VERSION "..\..\trunk\components\winTestMT\code\canApi\dbcFiles\canBus_09.dbc, created by Octave and generateRandomDbc.m on 21-Feb-2017"

NS_ :

BS_:

BU_: ECU

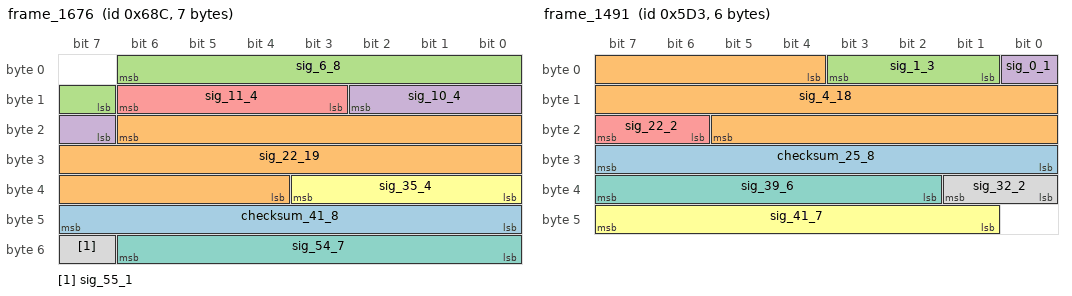
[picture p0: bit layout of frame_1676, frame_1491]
BO_ 1676 frame_1676: 7 ECU
  SG_ checksum_41_8 : 40|8@1+ (1.0,0.0) [0.0|255.0] "" Vector__XXX
  SG_ sig_22_19 : 22|19@0+ (0.1,31622.776601683792) [31622.776601683792|84051.37660168379] "km/h" Vector__XXX
  SG_ sig_6_8 : 6|8@0+ (10.0,-316.22776601683796) [-316.22776601683796|2223.772233983162] "W" Vector__XXX
  SG_ sig_10_4 : 10|4@0+ (1.0000000000000006E-5,-3.1622776601683795E-5) [-3.1622776601683795E-5|1.0837722339831631E-4] "s" Vector__XXX
  SG_ sig_11_4 : 11|4@1+ (1000.0,-3162.2776601683795) [-3162.2776601683795|10837.72233983162] "kWh" Vector__XXX
  SG_ sig_35_4 : 35|4@0+ (0.0010000000000000002,0.0) [0.0|0.014000000000000004] "s" Vector__XXX
  SG_ sig_54_7 : 54|7@0+ (1000.0,0.0) [0.0|126000.0] "s" Vector__XXX
  SG_ sig_55_1 : 55|1@0+ (1.0,0.0) [0.0|1.0] "" Vector__XXX

BO_ 1012 frame_1012: 4 Vector__XXX
  SG_ checksum_1_8 : 0|8@1+ (1.0,0.0) [0.0|255.0] "" ECU
  SG_ sig_8_14 : 8|14@0- (1.0,0.0) [-8192.0|8190.0] "" ECU
  SG_ sig_9_7 : 9|7@1+ (0.0010000000000000002,0.03162277660168379) [0.03162277660168379|0.15762277660168383] "km/h" ECU
  SG_ sig_24_3 : 24|3@1- (1.0,0.0) [-4.0|2.0] "" ECU

BO_ 1491 frame_1491: 6 ECU
  SG_ checksum_25_8 : 24|8@1+ (1.0,0.0) [0.0|255.0] "" Vector__XXX
  SG_ sig_4_18 : 4|18@1+ (1.0,0.0) [0.0|262142.0] "" Vector__XXX
  SG_ sig_1_3 : 1|3@1- (1.0,0.0) [-4.0|2.0] "" Vector__XXX
  SG_ sig_0_1 : 0|1@0+ (1.0,0.0) [0.0|1.0] "" Vector__XXX
  SG_ sig_22_2 : 22|2@1+ (1.0,0.0) [0.0|3.0] "" Vector__XXX
  SG_ sig_41_7 : 41|7@1+ (1.0,0.0) [0.0|126.0] "" Vector__XXX
  SG_ sig_39_6 : 39|6@0+ (1.0000000000000005E-4,0.0) [0.0|0.006200000000000002] "m/s^2" Vector__XXX
  SG_ sig_32_2 : 32|2@1- (1.0,0.0) [-2.0|1.0] "" Vector__XXX

BO_ 1536 frame_1536: 4 ECU
  SG_ checksum_9_8 : 15|8@0+ (1.0,0.0) [0.0|255.0] "" Vector__XXX
  SG_ sig_6_7 : 6|7@0- (1.0000000000000006E-6,0.0) [-6.400000000000004E-5|6.200000000000004E-5] "kWh" Vector__XXX
  SG_ sig_7_1 : 7|1@0+ (1.0,0.0) [0.0|1.0] "" Vector__XXX
  SG_ sig_17_10 : 17|10@0+ (1.0,0.0) [0.0|1022.0] "" Vector__XXX
  SG_ sig_19_2 : 19|2@0- (1.0,0.0) [-2.0|1.0] "" Vector__XXX

BO_ 499 frame_499: 4 Vector__XXX
  SG_ checksum_17_8 : 16|8@1+ (1.0,0.0) [0.0|255.0] "" ECU
  SG_ sig_1_15 : 1|15@1+ (1.0,0.0) [0.0|32766.0] "" ECU
  SG_ sig_0_1 : 0|1@1+ (1.0,0.0) [0.0|1.0] "" ECU
  SG_ sig_28_5 : 28|5@0+ (1.0,0.0) [0.0|30.0] "" ECU
  SG_ sig_31_3 : 31|3@0+ (1.0,0.0) [0.0|6.0] "" ECU

BO_ 621 frame_621: 4 ECU
  SG_ checksum_25_8 : 31|8@0+ (1.0,0.0) [0.0|255.0] "" Vector__XXX
  SG_ sig_3_14 : 3|14@0+ (1.0000000000000006E-6,0.0) [0.0|0.01638200000000001] "km/h" Vector__XXX
  SG_ sig_7_4 : 7|4@0+ (1.0,0.0) [0.0|14.0] "" Vector__XXX
  SG_ sig_20_5 : 20|5@0- (1.0,0.0) [-16.0|14.0] "" Vector__XXX
  SG_ sig_21_1 : 21|1@0+ (1.0,0.0) [0.0|1.0] "" Vector__XXX

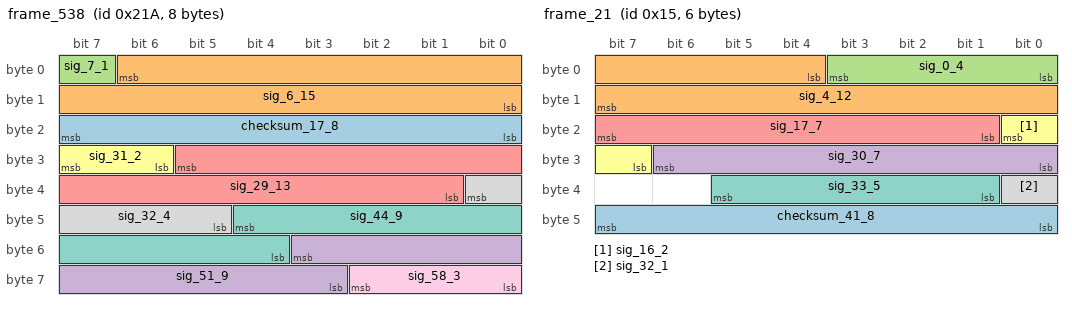
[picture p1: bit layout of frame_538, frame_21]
BO_ 538 frame_538: 8 ECU
  SG_ checksum_17_8 : 16|8@1+ (1.0,0.0) [0.0|255.0] "" Vector__XXX
  SG_ sig_6_15 : 6|15@0- (1.0,31622.776601683792) [15238.776601683792|48004.77660168379] "km/h" Vector__XXX
  SG_ sig_7_1 : 7|1@1+ (1.0,0.0) [0.0|1.0] "" Vector__XXX
  SG_ sig_51_9 : 51|9@0+ (1.0000000000000006E-5,0.0) [0.0|0.005100000000000003] "km/h" Vector__XXX
  SG_ sig_29_13 : 29|13@0+ (1.0,0.0) [0.0|8190.0] "" Vector__XXX
  SG_ sig_31_2 : 31|2@0- (1.0,0.0) [-2.0|1.0] "" Vector__XXX
  SG_ sig_44_9 : 44|9@0+ (1.0000000000000007E-7,-3.1622776601683795E-5) [-3.1622776601683795E-5|1.9377223398316245E-5] "s" Vector__XXX
  SG_ sig_32_4 : 32|4@0- (0.0010000000000000002,0.0) [-0.008000000000000002|0.006000000000000002] "W" Vector__XXX
  SG_ sig_58_3 : 58|3@0- (1.0,0.0) [-4.0|2.0] "" Vector__XXX

BO_ 1384 frame_1384: 7 ECU
  SG_ checksum_9_8 : 8|8@1+ (1.0,0.0) [0.0|255.0] "" Vector__XXX
  SG_ sig_0_7 : 0|7@1- (0.0010000000000000002,0.03162277660168379) [-0.032377223398316224|0.0936227766016838] "A" Vector__XXX
  SG_ sig_27_19 : 27|19@0+ (0.1,0.0) [0.0|52428.600000000006] "A" Vector__XXX
  SG_ sig_16_7 : 16|7@1+ (1.0,0.0) [0.0|126.0] "" Vector__XXX
  SG_ sig_28_4 : 28|4@1+ (1.0000000000000006E-6,3.162277660168379E-6) [3.162277660168379E-6|1.7162277660168386E-5] "km/h" Vector__XXX
  SG_ sig_48_8 : 48|8@1- (0.010000000000000002,0.0) [-1.2800000000000002|1.2600000000000002] "m/s^2" Vector__XXX

BO_ 993 frame_993: 7 Vector__XXX
  SG_ checksum_25_8 : 24|8@1+ (1.0,0.0) [0.0|255.0] "" ECU
  SG_ sig_0_18 : 0|18@1+ (1.0,0.0) [0.0|262142.0] "" ECU
  SG_ sig_18_6 : 18|6@1+ (1000.0,31622.776601683792) [31622.776601683792|93622.77660168378] "kWh" ECU
  SG_ sig_39_16 : 39|16@0+ (1.0,0.0) [0.0|65534.0] "" ECU
  SG_ sig_48_8 : 48|8@1+ (1.0000000000000005E-4,0.0031622776601683794) [0.0031622776601683794|0.028562277660168393] "km/h" ECU

BO_ 21 frame_21: 6 ECU
  SG_ checksum_41_8 : 47|8@0+ (1.0,0.0) [0.0|255.0] "" Vector__XXX
  SG_ sig_4_12 : 4|12@1- (10.0,31622.776601683792) [11142.776601683792|52082.77660168379] "W" Vector__XXX
  SG_ sig_0_4 : 0|4@1- (100.0,0.0) [-800.0|600.0] "kWh" Vector__XXX
  SG_ sig_30_7 : 30|7@0- (1.0,0.0) [-64.0|62.0] "" Vector__XXX
  SG_ sig_17_7 : 17|7@1- (1.0,0.0) [-64.0|62.0] "" Vector__XXX
  SG_ sig_16_2 : 16|2@0+ (1.0,0.0) [0.0|3.0] "" Vector__XXX
  SG_ sig_33_5 : 33|5@1- (1.0000000000000005E-4,-0.0031622776601683794) [-0.0047622776601683806|-0.0017622776601683788] "kWh" Vector__XXX
  SG_ sig_32_1 : 32|1@1+ (1.0,0.0) [0.0|1.0] "" Vector__XXX

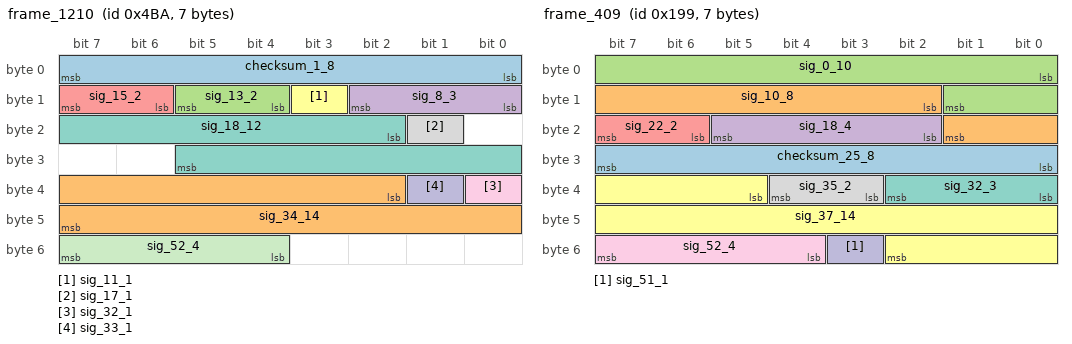
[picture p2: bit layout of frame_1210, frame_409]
BO_ 1210 frame_1210: 7 Vector__XXX
  SG_ checksum_1_8 : 7|8@0+ (1.0,0.0) [0.0|255.0] "" ECU
  SG_ sig_34_14 : 34|14@1- (10.0,-31622.776601683792) [-113542.77660168378|50277.22339831621] "km/h" ECU
  SG_ sig_13_2 : 13|2@0+ (1.0,0.0) [0.0|3.0] "" ECU
  SG_ sig_8_3 : 8|3@1- (1.0,0.0) [-4.0|2.0] "" ECU
  SG_ sig_15_2 : 15|2@0- (1.0,0.0) [-2.0|1.0] "" ECU
  SG_ sig_11_1 : 11|1@0+ (1.0,0.0) [0.0|1.0] "" ECU
  SG_ sig_18_12 : 18|12@1+ (1.0000000000000008E-8,0.0) [0.0|4.094000000000003E-5] "km/h" ECU
  SG_ sig_17_1 : 17|1@1+ (1.0,0.0) [0.0|1.0] "" ECU
  SG_ sig_32_1 : 32|1@1+ (1.0,0.0) [0.0|1.0] "" ECU
  SG_ sig_33_1 : 33|1@1+ (1.0,0.0) [0.0|1.0] "" ECU
  SG_ sig_52_4 : 52|4@1+ (1000.0,-3162.2776601683795) [-3162.2776601683795|10837.72233983162] "m/s^2" ECU

BO_ 566 frame_566: 6 Vector__XXX
  SG_ checksum_17_8 : 23|8@0+ (1.0,0.0) [0.0|255.0] "" ECU
  SG_ sig_6_14 : 6|14@0+ (1.0,0.0) [0.0|16382.0] "" ECU
  SG_ sig_7_1 : 7|1@0+ (1.0,0.0) [0.0|1.0] "" ECU
  SG_ sig_8_1 : 8|1@0+ (1.0,0.0) [0.0|1.0] "" ECU
  SG_ sig_31_16 : 31|16@0- (1.0,31622.776601683792) [-1145.2233983162077|64388.77660168379] "m/s^2" ECU
  SG_ sig_47_8 : 47|8@0+ (1.0,0.0) [0.0|254.0] "" ECU

BO_ 409 frame_409: 7 ECU
  SG_ checksum_25_8 : 24|8@1+ (1.0,0.0) [0.0|255.0] "" Vector__XXX
  SG_ sig_10_8 : 10|8@1- (100.0,0.0) [-12800.0|12600.0] "m/s^2" Vector__XXX
  SG_ sig_0_10 : 0|10@1- (1.0,0.0) [-512.0|510.0] "" Vector__XXX
  SG_ sig_18_4 : 18|4@1+ (10.0,0.0) [0.0|140.0] "s" Vector__XXX
  SG_ sig_22_2 : 22|2@1- (1.0,0.0) [-2.0|1.0] "" Vector__XXX
  SG_ sig_37_14 : 37|14@1- (1.0,0.0) [-8192.0|8190.0] "" Vector__XXX
  SG_ sig_32_3 : 32|3@1- (1.0,0.0) [-4.0|2.0] "" Vector__XXX
  SG_ sig_35_2 : 35|2@1- (1.0,0.0) [-2.0|1.0] "" Vector__XXX
  SG_ sig_52_4 : 52|4@1- (0.010000000000000002,0.0) [-0.08000000000000002|0.06000000000000001] "W" Vector__XXX
  SG_ sig_51_1 : 51|1@1+ (1.0,0.0) [0.0|1.0] "" Vector__XXX

BO_ 810 frame_810: 3 Vector__XXX
  SG_ checksum_9_8 : 8|8@1+ (1.0,0.0) [0.0|255.0] "" ECU
  SG_ sig_2_6 : 2|6@1+ (1.0,0.0) [0.0|62.0] "" ECU
  SG_ sig_0_2 : 0|2@1- (1.0,0.0) [-2.0|1.0] "" ECU
  SG_ sig_21_6 : 21|6@0- (1.0,0.0) [-32.0|30.0] "" ECU
  SG_ sig_23_2 : 23|2@0- (1.0,0.0) [-2.0|1.0] "" ECU

BO_ 1001 frame_1001: 5 Vector__XXX
  SG_ checksum_17_8 : 23|8@0+ (1.0,0.0) [0.0|255.0] "" ECU
  SG_ sig_3_12 : 3|12@1- (0.0010000000000000002,-3.1622776601683795) [-5.21027766016838|-1.1162776601683788] "W" ECU
  SG_ sig_2_4 : 2|4@0+ (1.0000000000000006E-6,3.162277660168379E-6) [3.162277660168379E-6|1.7162277660168386E-5] "km/h" ECU
  SG_ sig_31_13 : 31|13@0+ (1.0,0.0) [0.0|8190.0] "" ECU
  SG_ sig_32_1 : 32|1@0+ (1.0,0.0) [0.0|1.0] "" ECU

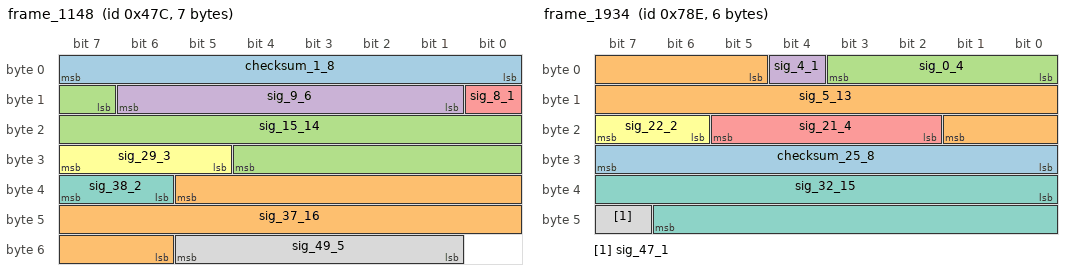
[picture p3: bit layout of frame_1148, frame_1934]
BO_ 1148 frame_1148: 7 ECU
  SG_ checksum_1_8 : 0|8@1+ (1.0,0.0) [0.0|255.0] "" Vector__XXX
  SG_ sig_37_16 : 37|16@0+ (0.010000000000000002,316.22776601683796) [316.22776601683796|971.567766016838] "s" Vector__XXX
  SG_ sig_15_14 : 15|14@1+ (0.1,316.22776601683796) [316.22776601683796|1954.427766016838] "A" Vector__XXX
  SG_ sig_9_6 : 9|6@1- (1000.0,31622.776601683792) [-377.22339831620775|61622.77660168379] "W" Vector__XXX
  SG_ sig_8_1 : 8|1@1+ (1.0,0.0) [0.0|1.0] "" Vector__XXX
  SG_ sig_29_3 : 29|3@1+ (1.0,0.0) [0.0|6.0] "" Vector__XXX
  SG_ sig_38_2 : 38|2@1+ (1.0,0.0) [0.0|3.0] "" Vector__XXX
  SG_ sig_49_5 : 49|5@1+ (100.0,-3162.2776601683795) [-3162.2776601683795|-162.2776601683795] "W" Vector__XXX

BO_ 1934 frame_1934: 6 ECU
  SG_ checksum_25_8 : 31|8@0+ (1.0,0.0) [0.0|255.0] "" Vector__XXX
  SG_ sig_5_13 : 5|13@1+ (1.0000000000000008E-8,-3.1622776601683795E-5) [-3.1622776601683795E-5|5.027722339831627E-5] "s" Vector__XXX
  SG_ sig_0_4 : 0|4@1- (1.0,0.0) [-8.0|6.0] "" Vector__XXX
  SG_ sig_4_1 : 4|1@0+ (1.0,0.0) [0.0|1.0] "" Vector__XXX
  SG_ sig_21_4 : 21|4@0+ (1.0000000000000006E-5,3.1622776601683795E-5) [3.1622776601683795E-5|1.7162277660168388E-4] "V" Vector__XXX
  SG_ sig_22_2 : 22|2@1+ (1.0,0.0) [0.0|3.0] "" Vector__XXX
  SG_ sig_32_15 : 32|15@1+ (1.0000000000000005E-4,3.1622776601683795) [3.1622776601683795|6.438877660168381] "kWh" Vector__XXX
  SG_ sig_47_1 : 47|1@0+ (1.0,0.0) [0.0|1.0] "" Vector__XXX

BO_ 1238 frame_1238: 6 Vector__XXX
  SG_ checksum_33_8 : 32|8@1+ (1.0,0.0) [0.0|255.0] "" ECU
  SG_ sig_1_16 : 1|16@1- (1.0000000000000005E-4,0.0) [-3.2768000000000015|3.2766000000000015] "m/s^2" ECU
  SG_ sig_0_1 : 0|1@1+ (1.0,0.0) [0.0|1.0] "" ECU
  SG_ sig_18_14 : 18|14@1- (10.0,-31622.776601683792) [-113542.77660168378|50277.22339831621] "kWh" ECU

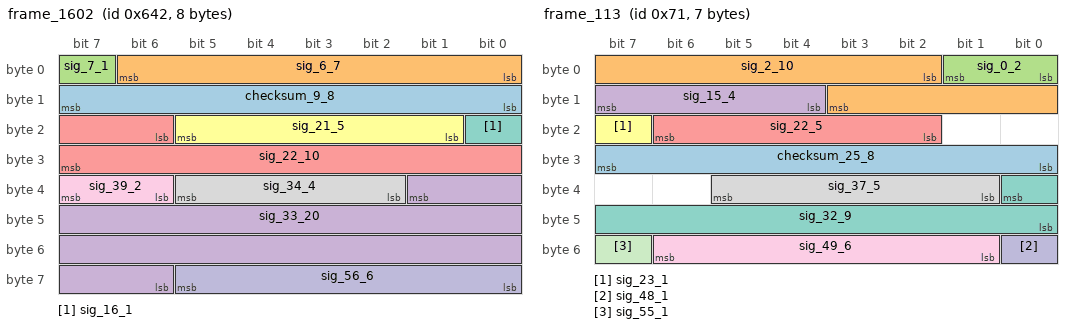
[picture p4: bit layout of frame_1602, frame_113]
BO_ 1602 frame_1602: 8 Vector__XXX
  SG_ checksum_9_8 : 15|8@0+ (1.0,0.0) [0.0|255.0] "" ECU
  SG_ sig_6_7 : 6|7@0+ (1.0,0.0) [0.0|126.0] "" ECU
  SG_ sig_7_1 : 7|1@0+ (1.0,0.0) [0.0|1.0] "" ECU
  SG_ sig_33_20 : 33|20@0- (1.0000000000000008E-8,0.0031622776601683794) [-0.002080602339831625|0.008405137660168384] "V" ECU
  SG_ sig_22_10 : 22|10@1- (0.010000000000000002,3.1622776601683795) [-1.9577223398316215|8.262277660168381] "kWh" ECU
  SG_ sig_21_5 : 21|5@0- (1.0000000000000005E-4,-0.0031622776601683794) [-0.0047622776601683806|-0.0017622776601683788] "V" ECU
  SG_ sig_16_1 : 16|1@1+ (1.0,0.0) [0.0|1.0] "" ECU
  SG_ sig_34_4 : 34|4@1+ (1.0,0.0) [0.0|14.0] "" ECU
  SG_ sig_39_2 : 39|2@0+ (1.0,0.0) [0.0|3.0] "" ECU
  SG_ sig_56_6 : 56|6@1+ (1.0000000000000007E-7,-3.162277660168379E-6) [-3.162277660168379E-6|3.037722339831626E-6] "km/h" ECU

BO_ 113 frame_113: 7 Vector__XXX
  SG_ checksum_25_8 : 24|8@1+ (1.0,0.0) [0.0|255.0] "" ECU
  SG_ sig_2_10 : 2|10@1+ (1.0,0.0) [0.0|1022.0] "" ECU
  SG_ sig_0_2 : 0|2@1- (1.0,0.0) [-2.0|1.0] "" ECU
  SG_ sig_15_4 : 15|4@0+ (1.0,0.0) [0.0|14.0] "" ECU
  SG_ sig_22_5 : 22|5@0- (1.0,0.0) [-16.0|14.0] "" ECU
  SG_ sig_23_1 : 23|1@0+ (1.0,0.0) [0.0|1.0] "" ECU
  SG_ sig_32_9 : 32|9@0- (1.0000000000000006E-6,-3.1622776601683794E-4) [-5.722277660168381E-4|-6.222776601683778E-5] "km/h" ECU
  SG_ sig_37_5 : 37|5@0- (1.0,0.0) [-16.0|14.0] "m/s^2" ECU
  SG_ sig_49_6 : 49|6@1- (1.0000000000000005E-4,0.0) [-0.0032000000000000015|0.0030000000000000014] "m/s^2" ECU
  SG_ sig_48_1 : 48|1@1+ (1.0,0.0) [0.0|1.0] "" ECU
  SG_ sig_55_1 : 55|1@0+ (1.0,0.0) [0.0|1.0] "" ECU

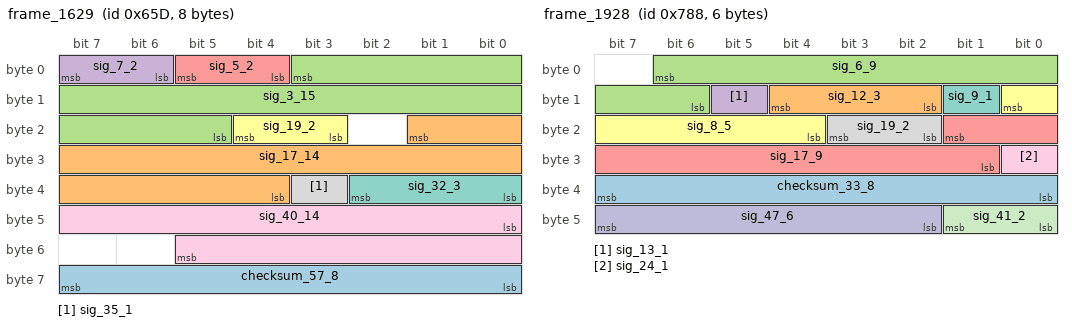
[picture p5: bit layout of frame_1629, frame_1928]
BO_ 1629 frame_1629: 8 Vector__XXX
  SG_ checksum_57_8 : 63|8@0+ (1.0,0.0) [0.0|255.0] "" ECU
  SG_ sig_17_14 : 17|14@0- (1.0,0.0) [-8192.0|8190.0] "s" ECU
  SG_ sig_3_15 : 3|15@0+ (1.0000000000000008E-8,-3.1622776601683794E-4) [-3.1622776601683794E-4|1.1432233983162349E-5] "km/h" ECU
  SG_ sig_7_2 : 7|2@0- (1.0,0.0) [-2.0|1.0] "" ECU
  SG_ sig_5_2 : 5|2@0+ (1.0,0.0) [0.0|3.0] "" ECU
  SG_ sig_19_2 : 19|2@1+ (1.0,0.0) [0.0|3.0] "" ECU
  SG_ sig_32_3 : 32|3@1+ (1.0,0.0) [0.0|6.0] "" ECU
  SG_ sig_35_1 : 35|1@1+ (1.0,0.0) [0.0|1.0] "" ECU
  SG_ sig_40_14 : 40|14@1- (1.0,0.0) [-8192.0|8190.0] "" ECU

BO_ 1928 frame_1928: 6 Vector__XXX
  SG_ checksum_33_8 : 39|8@0+ (1.0,0.0) [0.0|255.0] "" ECU
  SG_ sig_12_3 : 12|3@0+ (1.0,0.0) [0.0|6.0] "" ECU
  SG_ sig_6_9 : 6|9@0+ (1.0,0.0) [0.0|510.0] "V" ECU
  SG_ sig_13_1 : 13|1@0+ (1.0,0.0) [0.0|1.0] "" ECU
  SG_ sig_17_9 : 17|9@0- (1.0,0.0) [-256.0|254.0] "" ECU
  SG_ sig_8_5 : 8|5@0- (0.010000000000000002,0.31622776601683794) [0.1562277660168379|0.45622776601683795] "A" ECU
  SG_ sig_9_1 : 9|1@0+ (1.0,0.0) [0.0|1.0] "" ECU
  SG_ sig_19_2 : 19|2@0+ (1.0,0.0) [0.0|3.0] "" ECU
  SG_ sig_24_1 : 24|1@0+ (1.0,0.0) [0.0|1.0] "" ECU
  SG_ sig_47_6 : 47|6@0- (0.0010000000000000002,0.03162277660168379) [-3.7722339831621626E-4|0.0616227766016838] "s" ECU
  SG_ sig_41_2 : 41|2@0- (1.0,0.0) [-2.0|1.0] "" ECU

BO_ 1256 frame_1256: 6 Vector__XXX
  SG_ checksum_25_8 : 24|8@1+ (1.0,0.0) [0.0|255.0] "" ECU
  SG_ sig_5_20 : 5|20@0+ (1.0,0.0) [0.0|1048574.0] "" ECU
  SG_ sig_6_2 : 6|2@1+ (1.0,0.0) [0.0|3.0] "" ECU
  SG_ sig_16_2 : 16|2@1+ (1.0,0.0) [0.0|3.0] "" ECU
  SG_ sig_35_12 : 35|12@0+ (1.0,0.0) [0.0|4094.0] "V" ECU
  SG_ sig_39_4 : 39|4@0+ (0.1,0.0) [0.0|1.4000000000000001] "V" ECU

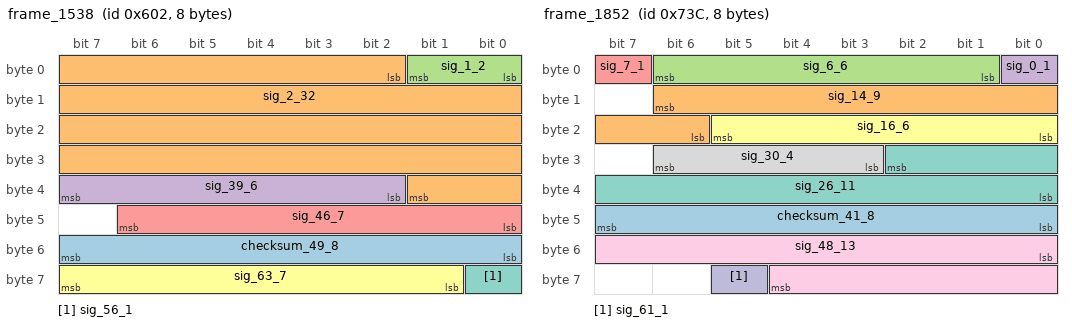
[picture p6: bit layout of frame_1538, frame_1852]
BO_ 1538 frame_1538: 8 ECU
  SG_ checksum_49_8 : 55|8@0+ (1.0,0.0) [0.0|255.0] "" Vector__XXX
  SG_ sig_2_32 : 2|32@1- (1.0000000000000011E-10,-0.31622776601683794) [-0.5309761308168381|-0.1014794014168377] "km/h" Vector__XXX
  SG_ sig_1_2 : 1|2@0- (1.0,0.0) [-2.0|1.0] "" Vector__XXX
  SG_ sig_39_6 : 39|6@0+ (1.0000000000000005E-4,0.0) [0.0|0.006200000000000002] "V" Vector__XXX
  SG_ sig_46_7 : 46|7@0- (1.0,0.0) [-64.0|62.0] "" Vector__XXX
  SG_ sig_63_7 : 63|7@0+ (1.0000000000000007E-7,-3.162277660168379E-6) [-3.162277660168379E-6|9.43772233983163E-6] "m/s^2" Vector__XXX
  SG_ sig_56_1 : 56|1@1+ (1.0,0.0) [0.0|1.0] "" Vector__XXX

BO_ 1852 frame_1852: 8 Vector__XXX
  SG_ checksum_41_8 : 47|8@0+ (1.0,0.0) [0.0|255.0] "" ECU
  SG_ sig_14_9 : 14|9@0+ (0.0010000000000000002,0.0) [0.0|0.5100000000000001] "A" ECU
  SG_ sig_6_6 : 6|6@0+ (0.010000000000000002,0.31622776601683794) [0.31622776601683794|0.9362277660168381] "A" ECU
  SG_ sig_0_1 : 0|1@1+ (1.0,0.0) [0.0|1.0] "" ECU
  SG_ sig_7_1 : 7|1@0+ (1.0,0.0) [0.0|1.0] "" ECU
  SG_ sig_16_6 : 16|6@1+ (100.0,0.0) [0.0|6200.0] "A" ECU
  SG_ sig_26_11 : 26|11@0- (1.0000000000000007E-7,3.1622776601683795E-5) [-7.077722339831629E-5|1.3382277660168386E-4] "A" ECU
  SG_ sig_30_4 : 30|4@0+ (1.0,0.0) [0.0|14.0] "" ECU
  SG_ sig_48_13 : 48|13@1+ (1.0,0.0) [0.0|8190.0] "" ECU
  SG_ sig_61_1 : 61|1@0+ (1.0,0.0) [0.0|1.0] "" ECU

BO_ 1146 frame_1146: 4 ECU
  SG_ checksum_17_8 : 16|8@1+ (1.0,0.0) [0.0|255.0] "" Vector__XXX
  SG_ sig_0_11 : 0|11@1+ (1.0,0.0) [0.0|2046.0] "V" Vector__XXX
  SG_ sig_11_5 : 11|5@1+ (1.0,0.0) [0.0|30.0] "" Vector__XXX
  SG_ sig_30_7 : 30|7@0+ (1.0,0.0) [0.0|126.0] "" Vector__XXX
  SG_ sig_31_1 : 31|1@1+ (1.0,0.0) [0.0|1.0] "" Vector__XXX

BO_ 1025 frame_1025: 5 ECU
  SG_ checksum_17_8 : 16|8@1+ (1.0,0.0) [0.0|255.0] "" Vector__XXX
  SG_ sig_1_15 : 1|15@1+ (1.0,0.0) [0.0|32766.0] "" Vector__XXX
  SG_ sig_0_1 : 0|1@1+ (1.0,0.0) [0.0|1.0] "" Vector__XXX
  SG_ sig_25_13 : 25|13@1- (1.0000000000000008E-8,0.0) [-4.0960000000000035E-5|4.094000000000003E-5] "A" Vector__XXX
  SG_ sig_24_1 : 24|1@1+ (1.0,0.0) [0.0|1.0] "" Vector__XXX
  SG_ sig_38_2 : 38|2@1+ (1.0,0.0) [0.0|3.0] "" Vector__XXX

BO_ 1610 frame_1610: 4 ECU
  SG_ checksum_9_8 : 15|8@0+ (1.0,0.0) [0.0|255.0] "" Vector__XXX
  SG_ sig_5_6 : 5|6@0- (1.0,0.0) [-32.0|30.0] "" Vector__XXX
  SG_ sig_6_2 : 6|2@1+ (1.0,0.0) [0.0|3.0] "" Vector__XXX
  SG_ sig_17_14 : 17|14@1+ (1.0,0.0) [0.0|16382.0] "" Vector__XXX
  SG_ sig_16_1 : 16|1@1+ (1.0,0.0) [0.0|1.0] "" Vector__XXX
  SG_ sig_31_1 : 31|1@1+ (1.0,0.0) [0.0|1.0] "" Vector__XXX

BO_ 1315 frame_1315: 7 ECU
  SG_ checksum_1_8 : 0|8@1+ (1.0,0.0) [0.0|255.0] "" Vector__XXX
  SG_ sig_18_31 : 18|31@1+ (1.000000000000001E-11,-0.0031622776601683794) [-0.0031622776601683794|0.01831255879983164] "s" Vector__XXX
  SG_ sig_13_5 : 13|5@1+ (1000.0,31622.776601683792) [31622.776601683792|61622.77660168379] "W" Vector__XXX
  SG_ sig_8_5 : 8|5@1+ (0.1,3.1622776601683795) [3.1622776601683795|6.16227766016838] "km/h" Vector__XXX
  SG_ sig_49_5 : 49|5@1- (1000.0,31622.776601683792) [15622.776601683792|45622.77660168379] "kWh" Vector__XXX
  SG_ sig_54_2 : 54|2@1- (1.0,0.0) [-2.0|1.0] "" Vector__XXX

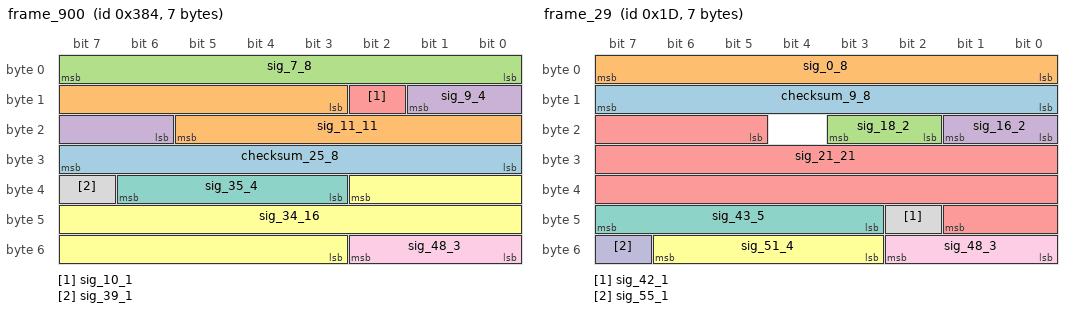
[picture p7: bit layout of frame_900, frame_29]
BO_ 900 frame_900: 7 ECU
  SG_ checksum_25_8 : 24|8@1+ (1.0,0.0) [0.0|255.0] "" Vector__XXX
  SG_ sig_11_11 : 11|11@1- (1.0000000000000006E-6,0.0) [-0.0010240000000000006|0.0010220000000000006] "V" Vector__XXX
  SG_ sig_7_8 : 7|8@0+ (1.0000000000000007E-7,-3.162277660168379E-6) [-3.162277660168379E-6|2.2237722339831637E-5] "m/s^2" Vector__XXX
  SG_ sig_9_4 : 9|4@0+ (10000.0,0.0) [0.0|140000.0] "km/h" Vector__XXX
  SG_ sig_10_1 : 10|1@0+ (1.0,0.0) [0.0|1.0] "" Vector__XXX
  SG_ sig_34_16 : 34|16@0+ (0.0010000000000000002,0.0) [0.0|65.53400000000002] "V" Vector__XXX
  SG_ sig_35_4 : 35|4@1+ (1.0,0.0) [0.0|14.0] "" Vector__XXX
  SG_ sig_39_1 : 39|1@0+ (1.0,0.0) [0.0|1.0] "" Vector__XXX
  SG_ sig_48_3 : 48|3@1+ (1.0,0.0) [0.0|6.0] "" Vector__XXX

BO_ 29 frame_29: 7 Vector__XXX
  SG_ checksum_9_8 : 15|8@0+ (1.0,0.0) [0.0|255.0] "" ECU
  SG_ sig_0_8 : 0|8@1- (0.010000000000000002,-0.31622776601683794) [-1.5962277660168382|0.9437722339831622] "W" ECU
  SG_ sig_18_2 : 18|2@1- (1.0,0.0) [-2.0|1.0] "" ECU
  SG_ sig_16_2 : 16|2@1- (1.0,0.0) [-2.0|1.0] "" ECU
  SG_ sig_21_21 : 21|21@1- (1.0000000000000006E-5,-3.1622776601683795) [-13.648037660168386|7.323462339831627] "kWh" ECU
  SG_ sig_51_4 : 51|4@1- (1.0,0.0) [-8.0|6.0] "" ECU
  SG_ sig_43_5 : 43|5@1- (1.0000000000000007E-7,3.162277660168379E-6) [1.562277660168378E-6|4.56227766016838E-6] "V" ECU
  SG_ sig_42_1 : 42|1@1+ (1.0,0.0) [0.0|1.0] "" ECU
  SG_ sig_48_3 : 48|3@1+ (1.0,0.0) [0.0|6.0] "" ECU
  SG_ sig_55_1 : 55|1@0+ (1.0,0.0) [0.0|1.0] "" ECU

BO_ 171 frame_171: 5 ECU
  SG_ checksum_9_8 : 8|8@1+ (1.0,0.0) [0.0|255.0] "" Vector__XXX
  SG_ sig_0_8 : 0|8@1- (0.0010000000000000002,0.0) [-0.12800000000000003|0.12600000000000003] "s" Vector__XXX
  SG_ sig_21_16 : 21|16@1- (1.0000000000000008E-8,3.1622776601683794E-4) [-1.1452233983162338E-5|6.438877660168382E-4] "V" Vector__XXX
  SG_ sig_16_5 : 16|5@1- (1.0,0.0) [-16.0|14.0] "" Vector__XXX

BO_ 240 frame_240: 5 ECU
  SG_ checksum_1_8 : 0|8@1+ (1.0,0.0) [0.0|255.0] "" Vector__XXX
  SG_ sig_15_17 : 15|17@1- (0.0010000000000000002,-31.622776601683793) [-97.15877660168381|33.911223398316224] "W" Vector__XXX
  SG_ sig_8_7 : 8|7@1+ (1000.0,0.0) [0.0|126000.0] "m/s^2" Vector__XXX
  SG_ sig_35_5 : 35|5@1+ (10.0,-316.22776601683796) [-316.22776601683796|-16.22776601683796] "kWh" Vector__XXX
  SG_ sig_32_3 : 32|3@1+ (1.0,0.0) [0.0|6.0] "" Vector__XXX

BO_ 726 frame_726: 8 Vector__XXX
  SG_ checksum_1_8 : 7|8@0+ (1.0,0.0) [0.0|255.0] "" ECU
  SG_ sig_14_25 : 14|25@0+ (1.0000000000000006E-5,0.0) [0.0|335.5443000000002] "W" ECU
  SG_ sig_15_1 : 15|1@1+ (1.0,0.0) [0.0|1.0] "" ECU
  SG_ sig_33_4 : 33|4@1+ (0.010000000000000002,0.0) [0.0|0.14] "kWh" ECU
  SG_ sig_37_1 : 37|1@0+ (1.0,0.0) [0.0|1.0] "" ECU
  SG_ sig_40_1 : 40|1@0+ (1.0,0.0) [0.0|1.0] "" ECU
  SG_ sig_63_8 : 63|8@0+ (100.0,3162.2776601683795) [3162.2776601683795|28562.27766016838] "kWh" ECU

BO_ 245 frame_245: 4 Vector__XXX
  SG_ checksum_25_8 : 31|8@0+ (1.0,0.0) [0.0|255.0] "" ECU
  SG_ sig_4_18 : 4|18@0+ (0.0010000000000000002,-31.622776601683793) [-31.622776601683793|230.51922339831626] "s" ECU
  SG_ sig_7_3 : 7|3@0+ (1.0,0.0) [0.0|6.0] "" ECU
  SG_ sig_18_2 : 18|2@0- (1.0,0.0) [-2.0|1.0] "" ECU
  SG_ sig_16_1 : 16|1@0+ (1.0,0.0) [0.0|1.0] "" ECU

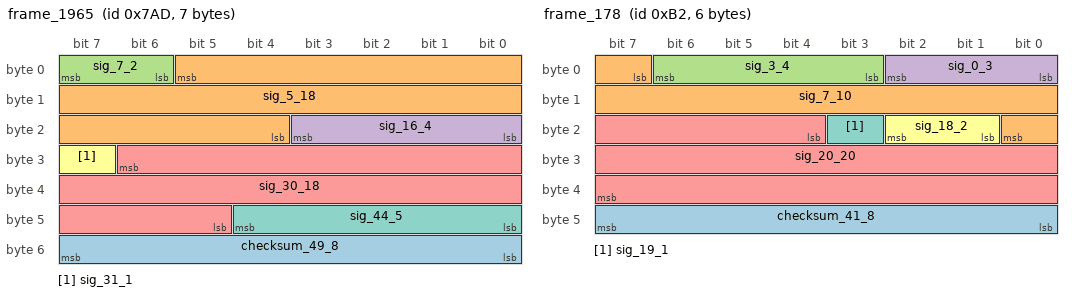
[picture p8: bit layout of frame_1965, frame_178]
BO_ 1965 frame_1965: 7 Vector__XXX
  SG_ checksum_49_8 : 48|8@1+ (1.0,0.0) [0.0|255.0] "" ECU
  SG_ sig_5_18 : 5|18@0+ (1.0000000000000007E-7,0.0031622776601683794) [0.0031622776601683794|0.0293764776601684] "W" ECU
  SG_ sig_7_2 : 7|2@0- (1.0,0.0) [-2.0|1.0] "" ECU
  SG_ sig_16_4 : 16|4@1- (1.0000000000000006E-5,-3.1622776601683795E-5) [-1.1162277660168384E-4|2.837722339831624E-5] "s" ECU
  SG_ sig_30_18 : 30|18@0- (1.0,0.0) [-131072.0|131070.0] "" ECU
  SG_ sig_31_1 : 31|1@1+ (1.0,0.0) [0.0|1.0] "" ECU
  SG_ sig_44_5 : 44|5@0+ (0.1,3.1622776601683795) [3.1622776601683795|6.16227766016838] "W" ECU

BO_ 178 frame_178: 6 ECU
  SG_ checksum_41_8 : 47|8@0+ (1.0,0.0) [0.0|255.0] "" Vector__XXX
  SG_ sig_7_10 : 7|10@1- (1.0000000000000007E-7,0.0) [-5.120000000000004E-5|5.100000000000004E-5] "V" Vector__XXX
  SG_ sig_3_4 : 3|4@1- (1.0,0.0) [-8.0|6.0] "" Vector__XXX
  SG_ sig_0_3 : 0|3@1- (1.0,0.0) [-4.0|2.0] "" Vector__XXX
  SG_ sig_20_20 : 20|20@1+ (0.1,31622.776601683792) [31622.776601683792|136480.1766016838] "A" Vector__XXX
  SG_ sig_18_2 : 18|2@0+ (1.0,0.0) [0.0|3.0] "" Vector__XXX
  SG_ sig_19_1 : 19|1@1+ (1.0,0.0) [0.0|1.0] "" Vector__XXX

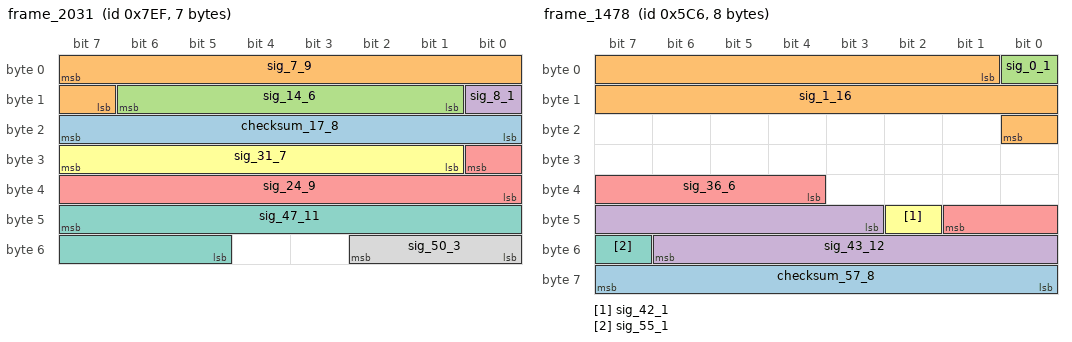
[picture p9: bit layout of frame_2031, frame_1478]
BO_ 2031 frame_2031: 7 ECU
  SG_ checksum_17_8 : 23|8@0+ (1.0,0.0) [0.0|255.0] "" Vector__XXX
  SG_ sig_7_9 : 7|9@0+ (1.0,0.0) [0.0|510.0] "" Vector__XXX
  SG_ sig_14_6 : 14|6@0+ (1.0000000000000006E-6,3.1622776601683795E-5) [3.1622776601683795E-5|9.362277660168383E-5] "kWh" Vector__XXX
  SG_ sig_8_1 : 8|1@0+ (1.0,0.0) [0.0|1.0] "" Vector__XXX
  SG_ sig_24_9 : 24|9@0- (1.0,316.22776601683796) [60.22776601683796|570.2277660168379] "km/h" Vector__XXX
  SG_ sig_31_7 : 31|7@0+ (1000.0,0.0) [0.0|126000.0] "km/h" Vector__XXX
  SG_ sig_47_11 : 47|11@0- (1.0,0.0) [-1024.0|1022.0] "" Vector__XXX
  SG_ sig_50_3 : 50|3@0- (1.0,0.0) [-4.0|2.0] "" Vector__XXX

BO_ 1393 frame_1393: 5 Vector__XXX
  SG_ checksum_25_8 : 24|8@1+ (1.0,0.0) [0.0|255.0] "" ECU
  SG_ sig_10_13 : 10|13@1+ (1.0000000000000006E-6,0.0031622776601683794) [0.0031622776601683794|0.011352277660168384] "kWh" ECU
  SG_ sig_1_9 : 1|9@1+ (1.0,0.0) [0.0|510.0] "" ECU
  SG_ sig_0_1 : 0|1@0+ (1.0,0.0) [0.0|1.0] "" ECU
  SG_ sig_23_1 : 23|1@1+ (1.0,0.0) [0.0|1.0] "" ECU
  SG_ sig_38_7 : 38|7@0- (0.0010000000000000002,0.0) [-0.06400000000000002|0.06200000000000001] "m/s^2" ECU

BO_ 1338 frame_1338: 3 Vector__XXX
  SG_ checksum_9_8 : 8|8@1+ (1.0,0.0) [0.0|255.0] "" ECU
  SG_ sig_3_4 : 3|4@0+ (0.010000000000000002,0.0) [0.0|0.14] "kWh" ECU
  SG_ sig_7_4 : 7|4@0+ (0.010000000000000002,-0.03162277660168379) [-0.03162277660168379|0.10837722339831622] "W" ECU
  SG_ sig_23_8 : 23|8@0+ (100.0,3162.2776601683795) [3162.2776601683795|28562.27766016838] "W" ECU

BO_ 1935 frame_1935: 8 ECU
  SG_ checksum_33_8 : 39|8@0+ (1.0,0.0) [0.0|255.0] "" Vector__XXX
  SG_ sig_0_8 : 0|8@1+ (1.0,0.0) [0.0|254.0] "" Vector__XXX
  SG_ sig_10_22 : 10|22@1+ (1.0000000000000011E-10,-3.1622776601683794E-4) [-3.1622776601683794E-4|1.032024339831625E-4] "km/h" Vector__XXX
  SG_ sig_8_2 : 8|2@1+ (1.0,0.0) [0.0|3.0] "" Vector__XXX
  SG_ sig_45_20 : 45|20@0- (0.1,31622.776601683792) [-20806.02339831621|84051.37660168379] "W" Vector__XXX
  SG_ sig_47_2 : 47|2@0- (1.0,0.0) [-2.0|1.0] "" Vector__XXX
  SG_ sig_56_2 : 56|2@1- (1.0,0.0) [-2.0|1.0] "" Vector__XXX

BO_ 1478 frame_1478: 8 Vector__XXX
  SG_ checksum_57_8 : 56|8@1+ (1.0,0.0) [0.0|255.0] "" ECU
  SG_ sig_1_16 : 1|16@1+ (1.0000000000000008E-8,-3.1622776601683794E-4) [-3.1622776601683794E-4|3.391122339831626E-4] "km/h" ECU
  SG_ sig_0_1 : 0|1@1+ (1.0,0.0) [0.0|1.0] "" ECU
  SG_ sig_43_12 : 43|12@1- (1.0,0.0) [-2048.0|2046.0] "" ECU
  SG_ sig_36_6 : 36|6@1- (0.010000000000000002,-0.31622776601683794) [-0.6362277660168381|-0.016227766016837897] "s" ECU
  SG_ sig_42_1 : 42|1@1+ (1.0,0.0) [0.0|1.0] "" ECU
  SG_ sig_55_1 : 55|1@1+ (1.0,0.0) [0.0|1.0] "" ECU

BO_ 1500 frame_1500: 4 Vector__XXX
  SG_ checksum_25_8 : 31|8@0+ (1.0,0.0) [0.0|255.0] "" ECU
  SG_ sig_14_14 : 14|14@0- (1.0,0.0) [-8192.0|8190.0] "s" ECU
  SG_ sig_6_8 : 6|8@0- (1000.0,31622.776601683792) [-96377.22339831622|157622.77660168378] "km/h" ECU

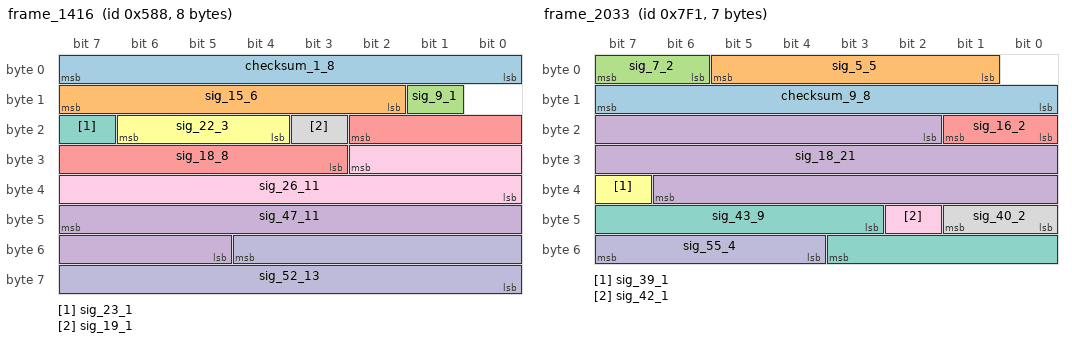
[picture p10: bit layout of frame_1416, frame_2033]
BO_ 1416 frame_1416: 8 ECU
  SG_ checksum_1_8 : 7|8@0+ (1.0,0.0) [0.0|255.0] "" Vector__XXX
  SG_ sig_15_6 : 15|6@0+ (1.0000000000000006E-6,-3.1622776601683795E-5) [-3.1622776601683795E-5|3.0377223398316248E-5] "W" Vector__XXX
  SG_ sig_9_1 : 9|1@0+ (1.0,0.0) [0.0|1.0] "" Vector__XXX
  SG_ sig_47_11 : 47|11@0- (0.0010000000000000002,0.0) [-1.0240000000000002|1.0220000000000002] "A" Vector__XXX
  SG_ sig_18_8 : 18|8@0+ (1.0,0.0) [0.0|254.0] "" Vector__XXX
  SG_ sig_22_3 : 22|3@0+ (1.0,0.0) [0.0|6.0] "" Vector__XXX
  SG_ sig_23_1 : 23|1@0+ (1.0,0.0) [0.0|1.0] "" Vector__XXX
  SG_ sig_19_1 : 19|1@0+ (1.0,0.0) [0.0|1.0] "" Vector__XXX
  SG_ sig_26_11 : 26|11@0- (1.0,0.0) [-1024.0|1022.0] "" Vector__XXX
  SG_ sig_52_13 : 52|13@0+ (1.0,0.0) [0.0|8190.0] "" Vector__XXX

BO_ 2033 frame_2033: 7 Vector__XXX
  SG_ checksum_9_8 : 15|8@0+ (1.0,0.0) [0.0|255.0] "" ECU
  SG_ sig_5_5 : 5|5@0- (1000.0,-31622.776601683792) [-47622.77660168379|-17622.776601683792] "W" ECU
  SG_ sig_7_2 : 7|2@0+ (1.0,0.0) [0.0|3.0] "" ECU
  SG_ sig_18_21 : 18|21@1+ (1.0000000000000011E-10,0.0) [0.0|2.0971500000000024E-4] "V" ECU
  SG_ sig_16_2 : 16|2@1- (1.0,0.0) [-2.0|1.0] "" ECU
  SG_ sig_39_1 : 39|1@0+ (1.0,0.0) [0.0|1.0] "" ECU
  SG_ sig_43_9 : 43|9@1+ (1.0000000000000006E-6,0.0) [0.0|5.100000000000003E-4] "m/s^2" ECU
  SG_ sig_40_2 : 40|2@1- (1.0,0.0) [-2.0|1.0] "" ECU
  SG_ sig_42_1 : 42|1@0+ (1.0,0.0) [0.0|1.0] "" ECU
  SG_ sig_55_4 : 55|4@0+ (1.0000000000000006E-6,0.0) [0.0|1.4000000000000008E-5] "A" ECU

BO_ 1058 frame_1058: 4 Vector__XXX
  SG_ checksum_1_8 : 7|8@0+ (1.0,0.0) [0.0|255.0] "" ECU
  SG_ sig_13_16 : 13|16@0+ (1.0,0.0) [0.0|65534.0] "" ECU
  SG_ sig_15_2 : 15|2@0- (1.0,0.0) [-2.0|1.0] "" ECU
  SG_ sig_28_4 : 28|4@0+ (0.010000000000000002,0.0) [0.0|0.14] "V" ECU
  SG_ sig_29_1 : 29|1@0+ (1.0,0.0) [0.0|1.0] "" ECU
  SG_ sig_24_1 : 24|1@0+ (1.0,0.0) [0.0|1.0] "" ECU

BO_ 223 frame_223: 7 Vector__XXX
  SG_ checksum_49_8 : 55|8@0+ (1.0,0.0) [0.0|255.0] "" ECU
  SG_ sig_4_21 : 4|21@1- (1.0000000000000006E-5,0.0) [-10.485760000000006|10.485740000000007] "V" ECU
  SG_ sig_0_4 : 0|4@1- (1.0000000000000005E-4,-3.1622776601683794E-4) [-0.0011162277660168383|2.8377223398316233E-4] "A" ECU
  SG_ sig_34_10 : 34|10@1+ (1.0,0.0) [0.0|1022.0] "" ECU
  SG_ sig_29_5 : 29|5@1+ (1.0,0.0) [0.0|30.0] "" ECU
  SG_ sig_25_4 : 25|4@1+ (1.0000000000000005E-4,3.1622776601683794E-4) [3.1622776601683794E-4|0.0017162277660168386] "V" ECU
  SG_ sig_47_4 : 47|4@0- (0.010000000000000002,-0.03162277660168379) [-0.1116227766016838|0.02837722339831622] "kWh" ECU

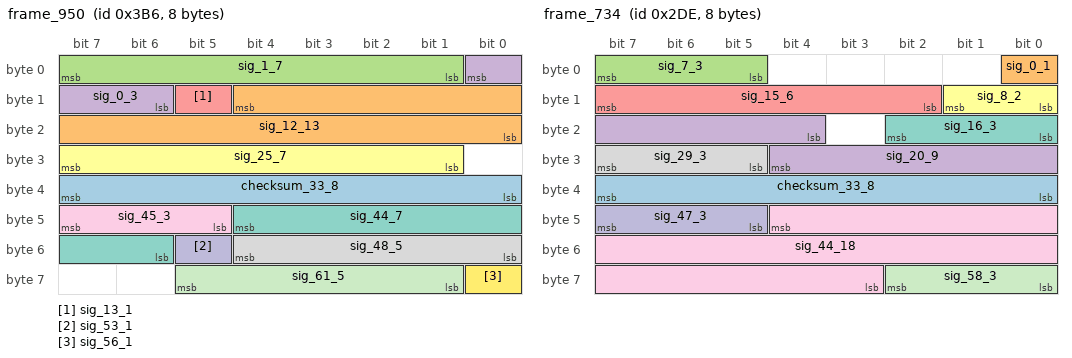
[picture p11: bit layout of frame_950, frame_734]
BO_ 950 frame_950: 8 ECU
  SG_ checksum_33_8 : 32|8@1+ (1.0,0.0) [0.0|255.0] "" Vector__XXX
  SG_ sig_12_13 : 12|13@0- (1.0000000000000007E-7,0.0) [-4.096000000000003E-4|4.094000000000003E-4] "kWh" Vector__XXX
  SG_ sig_1_7 : 1|7@1+ (1.0000000000000005E-4,-0.0031622776601683794) [-0.0031622776601683794|0.009437722339831625] "A" Vector__XXX
  SG_ sig_0_3 : 0|3@0- (1.0,0.0) [-4.0|2.0] "" Vector__XXX
  SG_ sig_13_1 : 13|1@0+ (1.0,0.0) [0.0|1.0] "" Vector__XXX
  SG_ sig_25_7 : 25|7@1- (0.1,0.0) [-6.4|6.2] "A" Vector__XXX
  SG_ sig_44_7 : 44|7@0+ (1.0,0.0) [0.0|126.0] "" Vector__XXX
  SG_ sig_48_5 : 48|5@1- (0.0010000000000000002,0.0) [-0.016000000000000004|0.014000000000000004] "m/s^2" Vector__XXX
  SG_ sig_45_3 : 45|3@1- (1.0,0.0) [-4.0|2.0] "" Vector__XXX
  SG_ sig_53_1 : 53|1@0+ (1.0,0.0) [0.0|1.0] "" Vector__XXX
  SG_ sig_61_5 : 61|5@0+ (1.0,0.0) [0.0|30.0] "m/s^2" Vector__XXX
  SG_ sig_56_1 : 56|1@1+ (1.0,0.0) [0.0|1.0] "" Vector__XXX

BO_ 734 frame_734: 8 ECU
  SG_ checksum_33_8 : 32|8@1+ (1.0,0.0) [0.0|255.0] "" Vector__XXX
  SG_ sig_0_1 : 0|1@1+ (1.0,0.0) [0.0|1.0] "" Vector__XXX
  SG_ sig_7_3 : 7|3@0+ (1.0,0.0) [0.0|6.0] "" Vector__XXX
  SG_ sig_20_9 : 20|9@1+ (1.0,0.0) [0.0|510.0] "" Vector__XXX
  SG_ sig_15_6 : 15|6@0- (1.0,0.0) [-32.0|30.0] "" Vector__XXX
  SG_ sig_8_2 : 8|2@1- (1.0,0.0) [-2.0|1.0] "" Vector__XXX
  SG_ sig_16_3 : 16|3@1- (1.0,0.0) [-4.0|2.0] "" Vector__XXX
  SG_ sig_29_3 : 29|3@1+ (1.0,0.0) [0.0|6.0] "" Vector__XXX
  SG_ sig_44_18 : 44|18@0+ (1.0000000000000005E-4,3.1622776601683795) [3.1622776601683795|29.37647766016839] "V" Vector__XXX
  SG_ sig_47_3 : 47|3@0- (1.0,0.0) [-4.0|2.0] "" Vector__XXX
  SG_ sig_58_3 : 58|3@0+ (1.0,0.0) [0.0|6.0] "" Vector__XXX

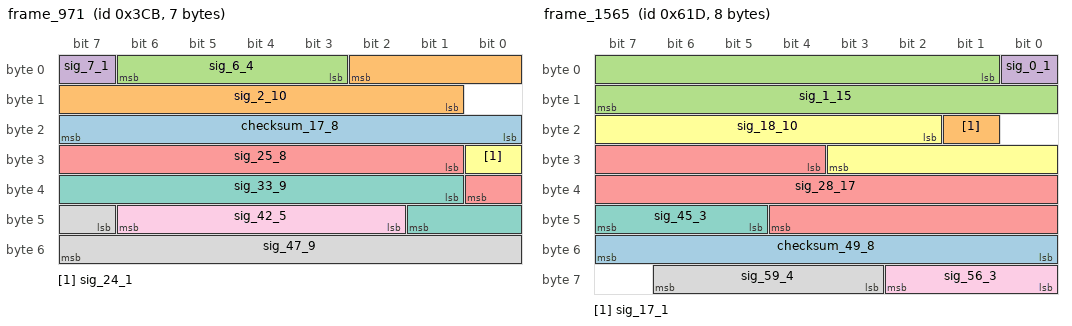
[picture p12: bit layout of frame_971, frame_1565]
BO_ 971 frame_971: 7 Vector__XXX
  SG_ checksum_17_8 : 23|8@0+ (1.0,0.0) [0.0|255.0] "" ECU
  SG_ sig_2_10 : 2|10@0- (10.0,0.0) [-5120.0|5100.0] "W" ECU
  SG_ sig_6_4 : 6|4@0+ (1.0000000000000006E-6,-3.162277660168379E-6) [-3.162277660168379E-6|1.0837722339831629E-5] "s" ECU
  SG_ sig_7_1 : 7|1@0+ (1.0,0.0) [0.0|1.0] "" ECU
  SG_ sig_25_8 : 25|8@1+ (1.0000000000000007E-7,-3.162277660168379E-6) [-3.162277660168379E-6|2.2237722339831637E-5] "W" ECU
  SG_ sig_24_1 : 24|1@1+ (1.0,0.0) [0.0|1.0] "" ECU
  SG_ sig_33_9 : 33|9@1+ (1.0,0.0) [0.0|510.0] "" ECU
  SG_ sig_47_9 : 47|9@1- (1.0,0.0) [-256.0|254.0] "" ECU
  SG_ sig_42_5 : 42|5@1- (1.0000000000000005E-4,0.0) [-0.0016000000000000007|0.0014000000000000006] "V" ECU

BO_ 1565 frame_1565: 8 ECU
  SG_ checksum_49_8 : 48|8@1+ (1.0,0.0) [0.0|255.0] "" Vector__XXX
  SG_ sig_17_1 : 17|1@1+ (1.0,0.0) [0.0|1.0] "" Vector__XXX
  SG_ sig_1_15 : 1|15@1- (0.0010000000000000002,0.0) [-16.384000000000004|16.382000000000005] "km/h" Vector__XXX
  SG_ sig_0_1 : 0|1@1+ (1.0,0.0) [0.0|1.0] "" Vector__XXX
  SG_ sig_28_17 : 28|17@1- (0.1,3162.2776601683795) [-3391.322339831621|9715.67766016838] "s" Vector__XXX
  SG_ sig_18_10 : 18|10@1+ (1.0,0.0) [0.0|1022.0] "" Vector__XXX
  SG_ sig_45_3 : 45|3@1- (1.0,0.0) [-4.0|2.0] "" Vector__XXX
  SG_ sig_59_4 : 59|4@1+ (1.0000000000000005E-4,-3.1622776601683794E-4) [-3.1622776601683794E-4|0.0010837722339831627] "A" Vector__XXX
  SG_ sig_56_3 : 56|3@1+ (1.0,0.0) [0.0|6.0] "" Vector__XXX

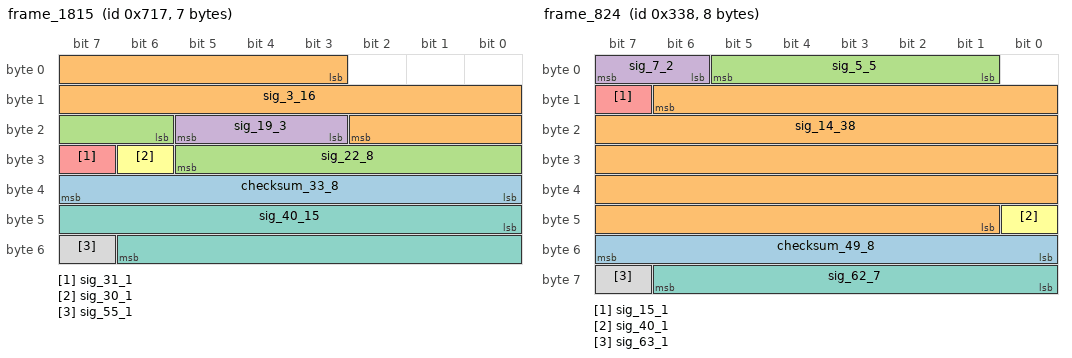
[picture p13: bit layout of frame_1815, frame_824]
BO_ 1815 frame_1815: 7 Vector__XXX
  SG_ checksum_33_8 : 32|8@1+ (1.0,0.0) [0.0|255.0] "" ECU
  SG_ sig_3_16 : 3|16@1- (0.0010000000000000002,31.622776601683793) [-1.1452233983162152|64.3887766016838] "m/s^2" ECU
  SG_ sig_22_8 : 22|8@1- (0.010000000000000002,0.0) [-1.2800000000000002|1.2600000000000002] "A" ECU
  SG_ sig_19_3 : 19|3@1+ (1.0,0.0) [0.0|6.0] "" ECU
  SG_ sig_31_1 : 31|1@0+ (1.0,0.0) [0.0|1.0] "" ECU
  SG_ sig_30_1 : 30|1@0+ (1.0,0.0) [0.0|1.0] "" ECU
  SG_ sig_40_15 : 40|15@1+ (1.0,0.0) [0.0|32766.0] "" ECU
  SG_ sig_55_1 : 55|1@1+ (1.0,0.0) [0.0|1.0] "" ECU

BO_ 824 frame_824: 8 Vector__XXX
  SG_ checksum_49_8 : 48|8@1+ (1.0,0.0) [0.0|255.0] "" ECU
  SG_ sig_14_38 : 14|38@0+ (1.0000000000000009E-9,-31.622776601683793) [-31.622776601683793|243.25513034031647] "A" ECU
  SG_ sig_5_5 : 5|5@0- (1.0,0.0) [-16.0|14.0] "" ECU
  SG_ sig_7_2 : 7|2@0+ (1.0,0.0) [0.0|3.0] "" ECU
  SG_ sig_15_1 : 15|1@1+ (1.0,0.0) [0.0|1.0] "" ECU
  SG_ sig_40_1 : 40|1@1+ (1.0,0.0) [0.0|1.0] "" ECU
  SG_ sig_62_7 : 62|7@0+ (1.0000000000000007E-7,0.0) [0.0|1.260000000000001E-5] "s" ECU
  SG_ sig_63_1 : 63|1@0+ (1.0,0.0) [0.0|1.0] "" ECU

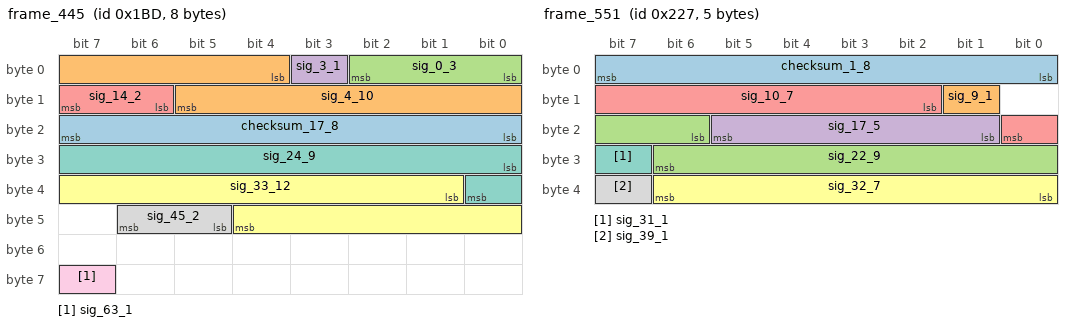
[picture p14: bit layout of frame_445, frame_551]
BO_ 445 frame_445: 8 Vector__XXX
  SG_ checksum_17_8 : 16|8@1+ (1.0,0.0) [0.0|255.0] "" ECU
  SG_ sig_4_10 : 4|10@1+ (1.0,0.0) [0.0|1022.0] "" ECU
  SG_ sig_0_3 : 0|3@1+ (1.0,0.0) [0.0|6.0] "" ECU
  SG_ sig_3_1 : 3|1@1+ (1.0,0.0) [0.0|1.0] "" ECU
  SG_ sig_14_2 : 14|2@1+ (1.0,0.0) [0.0|3.0] "" ECU
  SG_ sig_33_12 : 33|12@1+ (10.0,0.0) [0.0|40940.0] "m/s^2" ECU
  SG_ sig_24_9 : 24|9@1- (1.0000000000000005E-4,-0.03162277660168379) [-0.0572227766016838|-0.0062227766016837785] "s" ECU
  SG_ sig_45_2 : 45|2@1+ (1.0,0.0) [0.0|3.0] "" ECU
  SG_ sig_63_1 : 63|1@1+ (1.0,0.0) [0.0|1.0] "" ECU

BO_ 583 frame_583: 7 Vector__XXX
  SG_ checksum_33_8 : 39|8@0+ (1.0,0.0) [0.0|255.0] "" ECU
  SG_ sig_11_14 : 11|14@1- (1.0000000000000006E-6,0.0031622776601683794) [-0.005029722339831625|0.011352277660168384] "kWh" ECU
  SG_ sig_7_3 : 7|3@0- (1.0,0.0) [-4.0|2.0] "" ECU
  SG_ sig_1_2 : 1|2@0- (1.0,0.0) [-2.0|1.0] "" ECU
  SG_ sig_31_7 : 31|7@0+ (10.0,-316.22776601683796) [-316.22776601683796|943.7722339831621] "m/s^2" ECU
  SG_ sig_47_11 : 47|11@0- (1.0,0.0) [-1024.0|1022.0] "" ECU
  SG_ sig_51_3 : 51|3@0- (1.0,0.0) [-4.0|2.0] "" ECU

BO_ 1699 frame_1699: 6 ECU
  SG_ checksum_41_8 : 47|8@0+ (1.0,0.0) [0.0|255.0] "" Vector__XXX
  SG_ sig_17_6 : 17|6@0+ (1.0000000000000006E-5,3.1622776601683794E-4) [3.1622776601683794E-4|9.362277660168383E-4] "W" Vector__XXX
  SG_ sig_1_11 : 1|11@0- (1.0,0.0) [-1024.0|1022.0] "" Vector__XXX
  SG_ sig_7_6 : 7|6@0+ (1.0,0.0) [0.0|62.0] "" Vector__XXX
  SG_ sig_22_5 : 22|5@0+ (1.0,0.0) [0.0|30.0] "" Vector__XXX
  SG_ sig_26_10 : 26|10@0- (1.0000000000000007E-7,-3.1622776601683795E-5) [-8.282277660168384E-5|1.9377223398316245E-5] "V" Vector__XXX
  SG_ sig_32_1 : 32|1@0+ (1.0,0.0) [0.0|1.0] "" Vector__XXX

BO_ 551 frame_551: 5 Vector__XXX
  SG_ checksum_1_8 : 0|8@1+ (1.0,0.0) [0.0|255.0] "" ECU
  SG_ sig_9_1 : 9|1@1+ (1.0,0.0) [0.0|1.0] "" ECU
  SG_ sig_22_9 : 22|9@1+ (1.0,0.0) [0.0|510.0] "" ECU
  SG_ sig_17_5 : 17|5@1- (0.0010000000000000002,0.0) [-0.016000000000000004|0.014000000000000004] "kWh" ECU
  SG_ sig_10_7 : 10|7@1+ (1.0,0.0) [0.0|126.0] "" ECU
  SG_ sig_32_7 : 32|7@1+ (1000.0,31622.776601683792) [31622.776601683792|157622.77660168378] "m/s^2" ECU
  SG_ sig_31_1 : 31|1@1+ (1.0,0.0) [0.0|1.0] "" ECU
  SG_ sig_39_1 : 39|1@1+ (1.0,0.0) [0.0|1.0] "" ECU

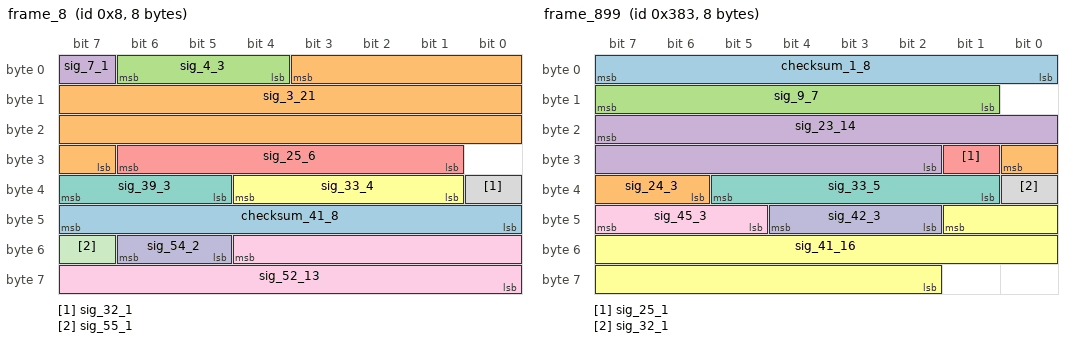
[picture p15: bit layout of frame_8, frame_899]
BO_ 8 frame_8: 8 Vector__XXX
  SG_ checksum_41_8 : 40|8@1+ (1.0,0.0) [0.0|255.0] "" ECU
  SG_ sig_3_21 : 3|21@0+ (1.0000000000000009E-9,-3.1622776601683794E-4) [-3.1622776601683794E-4|0.0017809222339831641] "m/s^2" ECU
  SG_ sig_4_3 : 4|3@1+ (1.0,0.0) [0.0|6.0] "" ECU
  SG_ sig_7_1 : 7|1@1+ (1.0,0.0) [0.0|1.0] "" ECU
  SG_ sig_25_6 : 25|6@1+ (1.0000000000000007E-7,3.162277660168379E-6) [3.162277660168379E-6|9.362277660168384E-6] "kWh" ECU
  SG_ sig_33_4 : 33|4@1+ (0.010000000000000002,0.03162277660168379) [0.03162277660168379|0.1716227766016838] "A" ECU
  SG_ sig_39_3 : 39|3@0- (1.0,0.0) [-4.0|2.0] "" ECU
  SG_ sig_32_1 : 32|1@0+ (1.0,0.0) [0.0|1.0] "" ECU
  SG_ sig_52_13 : 52|13@0- (0.1,316.22776601683796) [-93.37223398316206|725.627766016838] "V" ECU
  SG_ sig_54_2 : 54|2@0- (1.0,0.0) [-2.0|1.0] "" ECU
  SG_ sig_55_1 : 55|1@0+ (1.0,0.0) [0.0|1.0] "" ECU

BO_ 1698 frame_1698: 7 ECU
  SG_ checksum_9_8 : 15|8@0+ (1.0,0.0) [0.0|255.0] "" Vector__XXX
  SG_ sig_7_4 : 7|4@0- (10.0,-31.622776601683793) [-111.6227766016838|28.377223398316207] "A" Vector__XXX
  SG_ sig_1_2 : 1|2@0- (1.0,0.0) [-2.0|1.0] "" Vector__XXX
  SG_ sig_3_2 : 3|2@0- (1.0,0.0) [-2.0|1.0] "" Vector__XXX
  SG_ sig_23_31 : 23|31@0- (1.0000000000000009E-9,0.31622776601683794) [-0.757514057983163|1.389969588016839] "V" Vector__XXX
  SG_ sig_55_7 : 55|7@0- (10.0,0.0) [-640.0|620.0] "V" Vector__XXX
  SG_ sig_40_1 : 40|1@0+ (1.0,0.0) [0.0|1.0] "" Vector__XXX

BO_ 840 frame_840: 4 Vector__XXX
  SG_ checksum_25_8 : 24|8@1+ (1.0,0.0) [0.0|255.0] "" ECU
  SG_ sig_7_19 : 7|19@0- (1.0,0.0) [-262144.0|262142.0] "" ECU
  SG_ sig_20_5 : 20|5@0- (1.0000000000000005E-4,-0.0031622776601683794) [-0.0047622776601683806|-0.0017622776601683788] "A" ECU

BO_ 899 frame_899: 8 Vector__XXX
  SG_ checksum_1_8 : 0|8@1+ (1.0,0.0) [0.0|255.0] "" ECU
  SG_ sig_24_3 : 24|3@0+ (1.0,0.0) [0.0|6.0] "" ECU
  SG_ sig_9_7 : 9|7@1- (1.0000000000000006E-6,-3.1622776601683795E-5) [-9.562277660168383E-5|3.0377223398316248E-5] "W" ECU
  SG_ sig_23_14 : 23|14@0+ (1.0,0.0) [0.0|16382.0] "" ECU
  SG_ sig_25_1 : 25|1@1+ (1.0,0.0) [0.0|1.0] "" ECU
  SG_ sig_41_16 : 41|16@0- (0.010000000000000002,-316.22776601683796) [-643.907766016838|11.43223398316212] "A" ECU
  SG_ sig_33_5 : 33|5@1- (1.0,0.0) [-16.0|14.0] "" ECU
  SG_ sig_32_1 : 32|1@1+ (1.0,0.0) [0.0|1.0] "" ECU
  SG_ sig_45_3 : 45|3@1- (1.0,0.0) [-4.0|2.0] "" ECU
  SG_ sig_42_3 : 42|3@1- (1.0,0.0) [-4.0|2.0] "" ECU

BO_ 148 frame_148: 5 Vector__XXX
  SG_ checksum_1_8 : 7|8@0+ (1.0,0.0) [0.0|255.0] "" ECU
  SG_ sig_9_26 : 9|26@1- (0.0010000000000000002,0.0) [-33554.43200000001|33554.43000000001] "s" ECU
  SG_ sig_8_1 : 8|1@0+ (1.0,0.0) [0.0|1.0] "" ECU
  SG_ sig_35_1 : 35|1@1+ (1.0,0.0) [0.0|1.0] "" ECU

BO_ 1854 frame_1854: 8 ECU
  SG_ checksum_57_8 : 63|8@0+ (1.0,0.0) [0.0|255.0] "" Vector__XXX
  SG_ sig_2_6 : 2|6@1- (100.0,3162.2776601683795) [-37.7223398316205|6162.27766016838] "s" Vector__XXX
  SG_ sig_1_6 : 1|6@0- (0.0010000000000000002,-0.03162277660168379) [-0.0636227766016838|-0.0016227766016837855] "V" Vector__XXX
  SG_ sig_32_4 : 32|4@1- (1000.0,3162.2776601683795) [-4837.72233983162|9162.27766016838] "kWh" Vector__XXX
  SG_ sig_36_1 : 36|1@0+ (1.0,0.0) [0.0|1.0] "" Vector__XXX
  SG_ sig_40_11 : 40|11@1+ (1.0000000000000008E-8,-3.162277660168379E-6) [-3.162277660168379E-6|1.729772233983164E-5] "W" Vector__XXX
  SG_ sig_55_5 : 55|5@0- (1.0,0.0) [-16.0|14.0] "" Vector__XXX

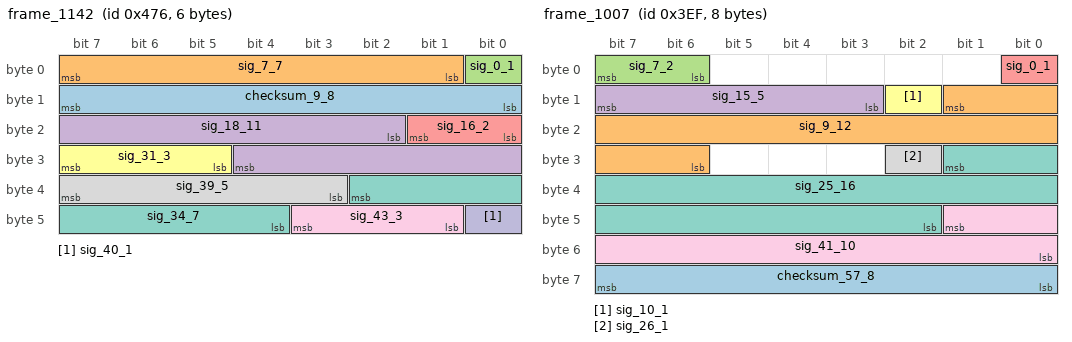
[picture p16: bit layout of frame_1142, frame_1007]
BO_ 1142 frame_1142: 6 ECU
  SG_ checksum_9_8 : 8|8@1+ (1.0,0.0) [0.0|255.0] "" Vector__XXX
  SG_ sig_7_7 : 7|7@0- (1.0,0.0) [-64.0|62.0] "" Vector__XXX
  SG_ sig_0_1 : 0|1@0+ (1.0,0.0) [0.0|1.0] "" Vector__XXX
  SG_ sig_18_11 : 18|11@1- (1.0,0.0) [-1024.0|1022.0] "" Vector__XXX
  SG_ sig_16_2 : 16|2@1- (1.0,0.0) [-2.0|1.0] "" Vector__XXX
  SG_ sig_31_3 : 31|3@0- (1.0,0.0) [-4.0|2.0] "" Vector__XXX
  SG_ sig_34_7 : 34|7@0- (1.0000000000000005E-4,-0.0031622776601683794) [-0.009562277660168383|0.003037722339831623] "km/h" Vector__XXX
  SG_ sig_39_5 : 39|5@0- (100.0,0.0) [-1600.0|1400.0] "W" Vector__XXX
  SG_ sig_43_3 : 43|3@0- (1.0,0.0) [-4.0|2.0] "" Vector__XXX
  SG_ sig_40_1 : 40|1@0+ (1.0,0.0) [0.0|1.0] "" Vector__XXX

BO_ 1007 frame_1007: 8 ECU
  SG_ checksum_57_8 : 63|8@0+ (1.0,0.0) [0.0|255.0] "" Vector__XXX
  SG_ sig_9_12 : 9|12@0- (1.0,0.0) [-2048.0|2046.0] "" Vector__XXX
  SG_ sig_7_2 : 7|2@0+ (1.0,0.0) [0.0|3.0] "" Vector__XXX
  SG_ sig_15_5 : 15|5@0- (100.0,0.0) [-1600.0|1400.0] "kWh" Vector__XXX
  SG_ sig_0_1 : 0|1@1+ (1.0,0.0) [0.0|1.0] "" Vector__XXX
  SG_ sig_10_1 : 10|1@0+ (1.0,0.0) [0.0|1.0] "" Vector__XXX
  SG_ sig_25_16 : 25|16@0- (1.0,0.0) [-32768.0|32766.0] "" Vector__XXX
  SG_ sig_26_1 : 26|1@0+ (1.0,0.0) [0.0|1.0] "" Vector__XXX
  SG_ sig_41_10 : 41|10@0- (0.1,31.622776601683793) [-19.57722339831621|82.6227766016838] "A" Vector__XXX

BO_ 1613 frame_1613: 6 ECU
  SG_ checksum_41_8 : 47|8@0+ (1.0,0.0) [0.0|255.0] "" Vector__XXX
  SG_ sig_2_17 : 2|17@0- (1.0,0.0) [-65536.0|65534.0] "" Vector__XXX
  SG_ sig_7_5 : 7|5@0- (1.0,31.622776601683793) [15.622776601683793|45.622776601683796] "km/h" Vector__XXX
  SG_ sig_16_2 : 16|2@1- (1.0,0.0) [-2.0|1.0] "" Vector__XXX
  SG_ sig_29_12 : 29|12@0+ (1.0000000000000007E-7,3.1622776601683794E-4) [3.1622776601683794E-4|7.256277660168382E-4] "W" Vector__XXX
  SG_ sig_31_2 : 31|2@0+ (1.0,0.0) [0.0|3.0] "" Vector__XXX
  SG_ sig_33_2 : 33|2@0- (1.0,0.0) [-2.0|1.0] "" Vector__XXX

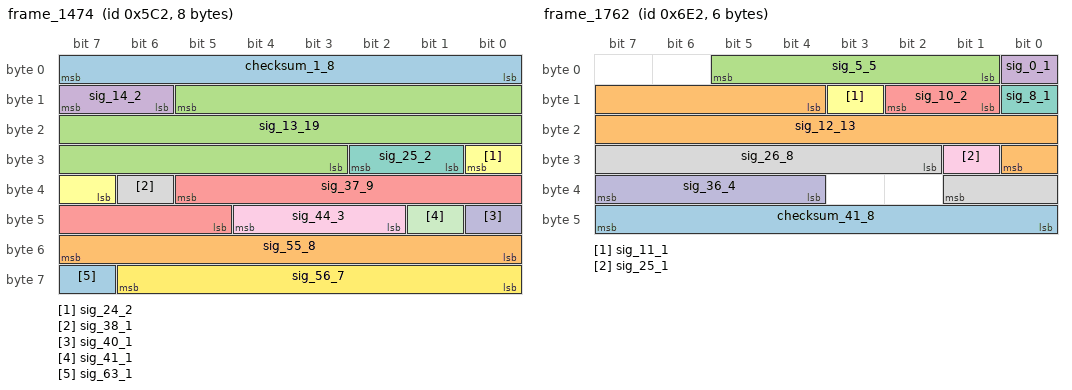
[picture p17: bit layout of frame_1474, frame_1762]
BO_ 1474 frame_1474: 8 Vector__XXX
  SG_ checksum_1_8 : 0|8@1+ (1.0,0.0) [0.0|255.0] "" ECU
  SG_ sig_55_8 : 55|8@0- (1.0000000000000006E-5,0.0) [-0.0012800000000000008|0.0012600000000000007] "s" ECU
  SG_ sig_13_19 : 13|19@0- (0.1,0.0) [-26214.4|26214.2] "A" ECU
  SG_ sig_14_2 : 14|2@1- (1.0,0.0) [-2.0|1.0] "" ECU
  SG_ sig_37_9 : 37|9@0+ (1.0000000000000007E-7,0.0) [0.0|5.100000000000004E-5] "kWh" ECU
  SG_ sig_24_2 : 24|2@0- (1.0,0.0) [-2.0|1.0] "" ECU
  SG_ sig_25_2 : 25|2@1+ (1.0,0.0) [0.0|3.0] "" ECU
  SG_ sig_38_1 : 38|1@0+ (1.0,0.0) [0.0|1.0] "" ECU
  SG_ sig_44_3 : 44|3@0+ (1.0,0.0) [0.0|6.0] "" ECU
  SG_ sig_40_1 : 40|1@0+ (1.0,0.0) [0.0|1.0] "" ECU
  SG_ sig_41_1 : 41|1@1+ (1.0,0.0) [0.0|1.0] "" ECU
  SG_ sig_56_7 : 56|7@1- (1.0000000000000005E-4,0.0031622776601683794) [-0.0032377223398316235|0.009362277660168382] "m/s^2" ECU
  SG_ sig_63_1 : 63|1@1+ (1.0,0.0) [0.0|1.0] "" ECU

BO_ 1762 frame_1762: 6 Vector__XXX
  SG_ checksum_41_8 : 47|8@0+ (1.0,0.0) [0.0|255.0] "" ECU
  SG_ sig_12_13 : 12|13@1+ (1.0000000000000008E-8,-3.1622776601683795E-5) [-3.1622776601683795E-5|5.027722339831627E-5] "kWh" ECU
  SG_ sig_5_5 : 5|5@0- (1.0,0.0) [-16.0|14.0] "" ECU
  SG_ sig_0_1 : 0|1@1+ (1.0,0.0) [0.0|1.0] "" ECU
  SG_ sig_10_2 : 10|2@0+ (1.0,0.0) [0.0|3.0] "" ECU
  SG_ sig_11_1 : 11|1@0+ (1.0,0.0) [0.0|1.0] "" ECU
  SG_ sig_8_1 : 8|1@1+ (1.0,0.0) [0.0|1.0] "" ECU
  SG_ sig_26_8 : 26|8@1+ (1.0,0.0) [0.0|254.0] "" ECU
  SG_ sig_25_1 : 25|1@1+ (1.0,0.0) [0.0|1.0] "" ECU
  SG_ sig_36_4 : 36|4@1+ (1.0,0.0) [0.0|14.0] "" ECU

BO_ 1121 frame_1121: 5 Vector__XXX
  SG_ checksum_9_8 : 15|8@0+ (1.0,0.0) [0.0|255.0] "" ECU
  SG_ sig_7_8 : 7|8@0+ (1.0,0.0) [0.0|254.0] "" ECU
  SG_ sig_19_18 : 19|18@0- (0.0010000000000000002,0.0) [-131.07200000000003|131.07000000000002] "s" ECU
  SG_ sig_23_3 : 23|3@0- (1.0,0.0) [-4.0|2.0] "" ECU
  SG_ sig_20_1 : 20|1@0+ (1.0,0.0) [0.0|1.0] "" ECU
  SG_ sig_33_2 : 33|2@0+ (1.0,0.0) [0.0|3.0] "" ECU

BO_ 1648 frame_1648: 6 Vector__XXX
  SG_ checksum_1_8 : 0|8@1+ (1.0,0.0) [0.0|255.0] "" ECU
  SG_ sig_8_15 : 8|15@0+ (1.0000000000000008E-8,3.1622776601683794E-4) [3.1622776601683794E-4|6.438877660168382E-4] "km/h" ECU
  SG_ sig_15_4 : 15|4@0+ (1.0,0.0) [0.0|14.0] "" ECU
  SG_ sig_24_2 : 24|2@1- (1.0,0.0) [-2.0|1.0] "" ECU
  SG_ sig_32_16 : 32|16@1+ (1.0000000000000008E-8,3.1622776601683794E-4) [3.1622776601683794E-4|9.715677660168385E-4] "A" ECU

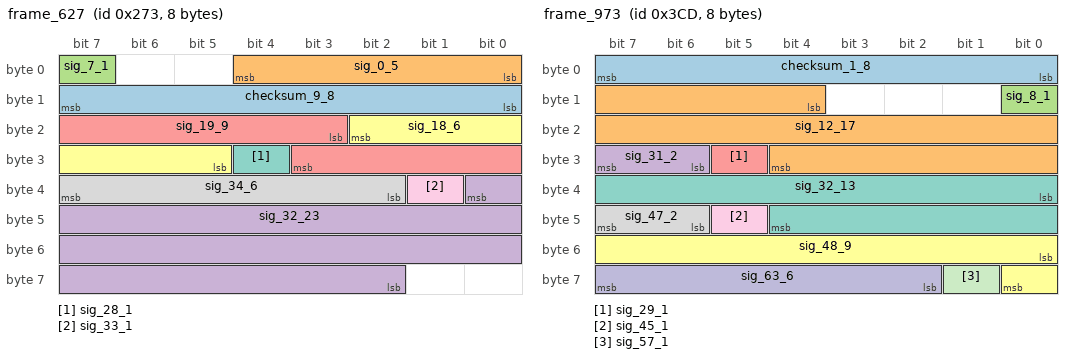
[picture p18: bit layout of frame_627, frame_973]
BO_ 627 frame_627: 8 ECU
  SG_ checksum_9_8 : 8|8@1+ (1.0,0.0) [0.0|255.0] "" Vector__XXX
  SG_ sig_0_5 : 0|5@1+ (1.0000000000000006E-6,-3.1622776601683795E-5) [-3.1622776601683795E-5|-1.6227766016837776E-6] "W" Vector__XXX
  SG_ sig_7_1 : 7|1@0+ (1.0,0.0) [0.0|1.0] "" Vector__XXX
  SG_ sig_32_23 : 32|23@0- (1.0000000000000005E-4,316.22776601683796) [-103.20263398316223|735.6579660168381] "kWh" Vector__XXX
  SG_ sig_19_9 : 19|9@1+ (1.0,-316.22776601683796) [-316.22776601683796|193.77223398316204] "V" Vector__XXX
  SG_ sig_18_6 : 18|6@0+ (1.0,0.0) [0.0|62.0] "" Vector__XXX
  SG_ sig_28_1 : 28|1@1+ (1.0,0.0) [0.0|1.0] "" Vector__XXX
  SG_ sig_34_6 : 34|6@1+ (1.0,-31.622776601683793) [-31.622776601683793|30.377223398316207] "s" Vector__XXX
  SG_ sig_33_1 : 33|1@1+ (1.0,0.0) [0.0|1.0] "" Vector__XXX

BO_ 1120 frame_1120: 6 Vector__XXX
  SG_ checksum_17_8 : 23|8@0+ (1.0,0.0) [0.0|255.0] "" ECU
  SG_ sig_0_16 : 0|16@1- (1.0000000000000005E-4,3.1622776601683795) [-0.11452233983162197|6.438877660168381] "kWh" ECU
  SG_ sig_26_19 : 26|19@1+ (1.0000000000000005E-4,-31.622776601683793) [-31.622776601683793|20.80582339831623] "m/s^2" ECU
  SG_ sig_25_2 : 25|2@0- (1.0,0.0) [-2.0|1.0] "" ECU
  SG_ sig_45_3 : 45|3@1+ (1.0,0.0) [0.0|6.0] "" ECU

BO_ 973 frame_973: 8 ECU
  SG_ checksum_1_8 : 0|8@1+ (1.0,0.0) [0.0|255.0] "" Vector__XXX
  SG_ sig_12_17 : 12|17@1+ (0.010000000000000002,-316.22776601683796) [-316.22776601683796|994.4722339831624] "V" Vector__XXX
  SG_ sig_8_1 : 8|1@0+ (1.0,0.0) [0.0|1.0] "" Vector__XXX
  SG_ sig_31_2 : 31|2@0- (1.0,0.0) [-2.0|1.0] "" Vector__XXX
  SG_ sig_29_1 : 29|1@0+ (1.0,0.0) [0.0|1.0] "" Vector__XXX
  SG_ sig_48_9 : 48|9@1- (1.0000000000000006E-6,-3.1622776601683794E-4) [-5.722277660168381E-4|-6.222776601683778E-5] "km/h" Vector__XXX
  SG_ sig_32_13 : 32|13@1+ (0.0010000000000000002,-3.1622776601683795) [-3.1622776601683795|5.027722339831621] "km/h" Vector__XXX
  SG_ sig_47_2 : 47|2@0+ (1.0,0.0) [0.0|3.0] "" Vector__XXX
  SG_ sig_45_1 : 45|1@1+ (1.0,0.0) [0.0|1.0] "" Vector__XXX
  SG_ sig_63_6 : 63|6@0- (10.0,0.0) [-320.0|300.0] "km/h" Vector__XXX
  SG_ sig_57_1 : 57|1@0+ (1.0,0.0) [0.0|1.0] "" Vector__XXX

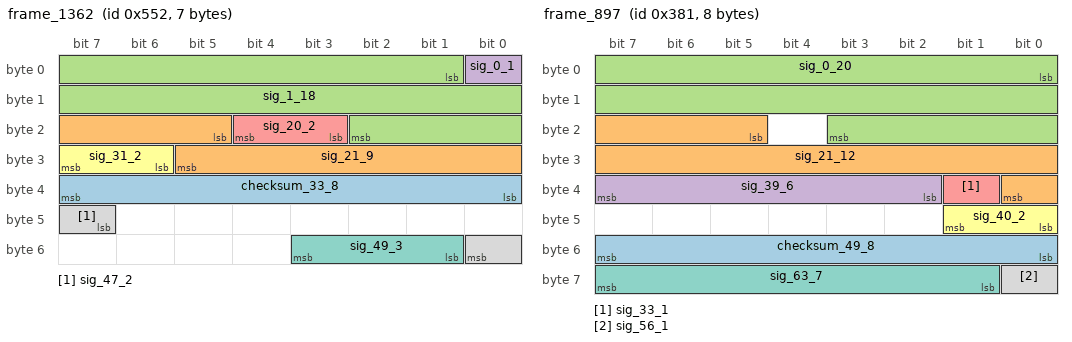
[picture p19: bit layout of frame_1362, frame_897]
BO_ 1362 frame_1362: 7 ECU
  SG_ checksum_33_8 : 32|8@1+ (1.0,0.0) [0.0|255.0] "" Vector__XXX
  SG_ sig_21_9 : 21|9@1- (1.0000000000000007E-7,3.1622776601683795E-5) [6.022776601683776E-6|5.702277660168381E-5] "V" Vector__XXX
  SG_ sig_1_18 : 1|18@1+ (1.0,0.0) [0.0|262142.0] "" Vector__XXX
  SG_ sig_0_1 : 0|1@1+ (1.0,0.0) [0.0|1.0] "" Vector__XXX
  SG_ sig_20_2 : 20|2@0- (1.0,0.0) [-2.0|1.0] "" Vector__XXX
  SG_ sig_31_2 : 31|2@0- (1.0,0.0) [-2.0|1.0] "" Vector__XXX
  SG_ sig_49_3 : 49|3@1- (1.0,0.0) [-4.0|2.0] "" Vector__XXX
  SG_ sig_47_2 : 47|2@1+ (1.0,0.0) [0.0|3.0] "" Vector__XXX

BO_ 897 frame_897: 8 Vector__XXX
  SG_ checksum_49_8 : 48|8@1+ (1.0,0.0) [0.0|255.0] "" ECU
  SG_ sig_21_12 : 21|12@1- (1.0,0.0) [-2048.0|2046.0] "" ECU
  SG_ sig_0_20 : 0|20@1+ (1.0000000000000009E-9,3.1622776601683794E-4) [3.1622776601683794E-4|0.0013648017660168388] "A" ECU
  SG_ sig_39_6 : 39|6@0- (1.0,0.0) [-32.0|30.0] "W" ECU
  SG_ sig_33_1 : 33|1@0+ (1.0,0.0) [0.0|1.0] "" ECU
  SG_ sig_40_2 : 40|2@1- (1.0,0.0) [-2.0|1.0] "" ECU
  SG_ sig_63_7 : 63|7@0+ (1000.0,-31622.776601683792) [-31622.776601683792|94377.22339831622] "A" ECU
  SG_ sig_56_1 : 56|1@1+ (1.0,0.0) [0.0|1.0] "" ECU

CM_ BO_ 1676 "Randomly defined CAN frame";
CM_ SG_ 1676 checksum_41_8 "8 Bit checksum for protection of frame contents";
CM_ BO_ 1012 "Randomly defined CAN frame";
CM_ SG_ 1012 checksum_1_8 "8 Bit checksum for protection of frame contents";
CM_ BO_ 1491 "Randomly defined CAN frame";
CM_ SG_ 1491 checksum_25_8 "8 Bit checksum for protection of frame contents";
CM_ BO_ 1536 "Randomly defined CAN frame";
CM_ SG_ 1536 checksum_9_8 "8 Bit checksum for protection of frame contents";
CM_ BO_ 499 "Randomly defined CAN frame";
CM_ SG_ 499 checksum_17_8 "8 Bit checksum for protection of frame contents";
CM_ BO_ 621 "Randomly defined CAN frame";
CM_ SG_ 621 checksum_25_8 "8 Bit checksum for protection of frame contents";
CM_ BO_ 538 "Randomly defined CAN frame";
CM_ SG_ 538 checksum_17_8 "8 Bit checksum for protection of frame contents";
CM_ BO_ 1384 "Randomly defined CAN frame";
CM_ SG_ 1384 checksum_9_8 "8 Bit checksum for protection of frame contents";
CM_ BO_ 993 "Randomly defined CAN frame";
CM_ SG_ 993 checksum_25_8 "8 Bit checksum for protection of frame contents";
CM_ BO_ 21 "Randomly defined CAN frame";
CM_ SG_ 21 checksum_41_8 "8 Bit checksum for protection of frame contents";
CM_ BO_ 1210 "Randomly defined CAN frame";
CM_ SG_ 1210 checksum_1_8 "8 Bit checksum for protection of frame contents";
CM_ BO_ 566 "Randomly defined CAN frame";
CM_ SG_ 566 checksum_17_8 "8 Bit checksum for protection of frame contents";
CM_ BO_ 409 "Randomly defined CAN frame";
CM_ SG_ 409 checksum_25_8 "8 Bit checksum for protection of frame contents";
CM_ BO_ 810 "Randomly defined CAN frame";
CM_ SG_ 810 checksum_9_8 "8 Bit checksum for protection of frame contents";
CM_ BO_ 1001 "Randomly defined CAN frame";
CM_ SG_ 1001 checksum_17_8 "8 Bit checksum for protection of frame contents";
CM_ BO_ 1148 "Randomly defined CAN frame";
CM_ SG_ 1148 checksum_1_8 "8 Bit checksum for protection of frame contents";
CM_ BO_ 1934 "Randomly defined CAN frame";
CM_ SG_ 1934 checksum_25_8 "8 Bit checksum for protection of frame contents";
CM_ BO_ 1238 "Randomly defined CAN frame";
CM_ SG_ 1238 checksum_33_8 "8 Bit checksum for protection of frame contents";
CM_ BO_ 1602 "Randomly defined CAN frame";
CM_ SG_ 1602 checksum_9_8 "8 Bit checksum for protection of frame contents";
CM_ BO_ 113 "Randomly defined CAN frame";
CM_ SG_ 113 checksum_25_8 "8 Bit checksum for protection of frame contents";
CM_ BO_ 1629 "Randomly defined CAN frame";
CM_ SG_ 1629 checksum_57_8 "8 Bit checksum for protection of frame contents";
CM_ BO_ 1928 "Randomly defined CAN frame";
CM_ SG_ 1928 checksum_33_8 "8 Bit checksum for protection of frame contents";
CM_ BO_ 1256 "Randomly defined CAN frame";
CM_ SG_ 1256 checksum_25_8 "8 Bit checksum for protection of frame contents";
CM_ BO_ 1538 "Randomly defined CAN frame";
CM_ SG_ 1538 checksum_49_8 "8 Bit checksum for protection of frame contents";
CM_ BO_ 1852 "Randomly defined CAN frame";
CM_ SG_ 1852 checksum_41_8 "8 Bit checksum for protection of frame contents";
CM_ BO_ 1146 "Randomly defined CAN frame";
CM_ SG_ 1146 checksum_17_8 "8 Bit checksum for protection of frame contents";
CM_ BO_ 1025 "Randomly defined CAN frame";
CM_ SG_ 1025 checksum_17_8 "8 Bit checksum for protection of frame contents";
CM_ BO_ 1610 "Randomly defined CAN frame";
CM_ SG_ 1610 checksum_9_8 "8 Bit checksum for protection of frame contents";
CM_ BO_ 1315 "Randomly defined CAN frame";
CM_ SG_ 1315 checksum_1_8 "8 Bit checksum for protection of frame contents";
CM_ BO_ 900 "Randomly defined CAN frame";
CM_ SG_ 900 checksum_25_8 "8 Bit checksum for protection of frame contents";
CM_ BO_ 29 "Randomly defined CAN frame";
CM_ SG_ 29 checksum_9_8 "8 Bit checksum for protection of frame contents";
CM_ BO_ 171 "Randomly defined CAN frame";
CM_ SG_ 171 checksum_9_8 "8 Bit checksum for protection of frame contents";
CM_ BO_ 240 "Randomly defined CAN frame";
CM_ SG_ 240 checksum_1_8 "8 Bit checksum for protection of frame contents";
CM_ BO_ 726 "Randomly defined CAN frame";
CM_ SG_ 726 checksum_1_8 "8 Bit checksum for protection of frame contents";
CM_ BO_ 245 "Randomly defined CAN frame";
CM_ SG_ 245 checksum_25_8 "8 Bit checksum for protection of frame contents";
CM_ BO_ 1965 "Randomly defined CAN frame";
CM_ SG_ 1965 checksum_49_8 "8 Bit checksum for protection of frame contents";
CM_ BO_ 178 "Randomly defined CAN frame";
CM_ SG_ 178 checksum_41_8 "8 Bit checksum for protection of frame contents";
CM_ BO_ 2031 "Randomly defined CAN frame";
CM_ SG_ 2031 checksum_17_8 "8 Bit checksum for protection of frame contents";
CM_ BO_ 1393 "Randomly defined CAN frame";
CM_ SG_ 1393 checksum_25_8 "8 Bit checksum for protection of frame contents";
CM_ BO_ 1338 "Randomly defined CAN frame";
CM_ SG_ 1338 checksum_9_8 "8 Bit checksum for protection of frame contents";
CM_ BO_ 1935 "Randomly defined CAN frame";
CM_ SG_ 1935 checksum_33_8 "8 Bit checksum for protection of frame contents";
CM_ BO_ 1478 "Randomly defined CAN frame";
CM_ SG_ 1478 checksum_57_8 "8 Bit checksum for protection of frame contents";
CM_ BO_ 1500 "Randomly defined CAN frame";
CM_ SG_ 1500 checksum_25_8 "8 Bit checksum for protection of frame contents";
CM_ BO_ 1416 "Randomly defined CAN frame";
CM_ SG_ 1416 checksum_1_8 "8 Bit checksum for protection of frame contents";
CM_ BO_ 2033 "Randomly defined CAN frame";
CM_ SG_ 2033 checksum_9_8 "8 Bit checksum for protection of frame contents";
CM_ BO_ 1058 "Randomly defined CAN frame";
CM_ SG_ 1058 checksum_1_8 "8 Bit checksum for protection of frame contents";
CM_ BO_ 223 "Randomly defined CAN frame";
CM_ SG_ 223 checksum_49_8 "8 Bit checksum for protection of frame contents";
CM_ BO_ 950 "Randomly defined CAN frame";
CM_ SG_ 950 checksum_33_8 "8 Bit checksum for protection of frame contents";
CM_ BO_ 734 "Randomly defined CAN frame";
CM_ SG_ 734 checksum_33_8 "8 Bit checksum for protection of frame contents";
CM_ BO_ 971 "Randomly defined CAN frame";
CM_ SG_ 971 checksum_17_8 "8 Bit checksum for protection of frame contents";
CM_ BO_ 1565 "Randomly defined CAN frame";
CM_ SG_ 1565 checksum_49_8 "8 Bit checksum for protection of frame contents";
CM_ BO_ 1815 "Randomly defined CAN frame";
CM_ SG_ 1815 checksum_33_8 "8 Bit checksum for protection of frame contents";
CM_ BO_ 824 "Randomly defined CAN frame";
CM_ SG_ 824 checksum_49_8 "8 Bit checksum for protection of frame contents";
CM_ BO_ 445 "Randomly defined CAN frame";
CM_ SG_ 445 checksum_17_8 "8 Bit checksum for protection of frame contents";
CM_ BO_ 583 "Randomly defined CAN frame";
CM_ SG_ 583 checksum_33_8 "8 Bit checksum for protection of frame contents";
CM_ BO_ 1699 "Randomly defined CAN frame";
CM_ SG_ 1699 checksum_41_8 "8 Bit checksum for protection of frame contents";
CM_ BO_ 551 "Randomly defined CAN frame";
CM_ SG_ 551 checksum_1_8 "8 Bit checksum for protection of frame contents";
CM_ BO_ 8 "Randomly defined CAN frame";
CM_ SG_ 8 checksum_41_8 "8 Bit checksum for protection of frame contents";
CM_ BO_ 1698 "Randomly defined CAN frame";
CM_ SG_ 1698 checksum_9_8 "8 Bit checksum for protection of frame contents";
CM_ BO_ 840 "Randomly defined CAN frame";
CM_ SG_ 840 checksum_25_8 "8 Bit checksum for protection of frame contents";
CM_ BO_ 899 "Randomly defined CAN frame";
CM_ SG_ 899 checksum_1_8 "8 Bit checksum for protection of frame contents";
CM_ BO_ 148 "Randomly defined CAN frame";
CM_ SG_ 148 checksum_1_8 "8 Bit checksum for protection of frame contents";
CM_ BO_ 1854 "Randomly defined CAN frame";
CM_ SG_ 1854 checksum_57_8 "8 Bit checksum for protection of frame contents";
CM_ BO_ 1142 "Randomly defined CAN frame";
CM_ SG_ 1142 checksum_9_8 "8 Bit checksum for protection of frame contents";
CM_ BO_ 1007 "Randomly defined CAN frame";
CM_ SG_ 1007 checksum_57_8 "8 Bit checksum for protection of frame contents";
CM_ BO_ 1613 "Randomly defined CAN frame";
CM_ SG_ 1613 checksum_41_8 "8 Bit checksum for protection of frame contents";
CM_ BO_ 1474 "Randomly defined CAN frame";
CM_ SG_ 1474 checksum_1_8 "8 Bit checksum for protection of frame contents";
CM_ BO_ 1762 "Randomly defined CAN frame";
CM_ SG_ 1762 checksum_41_8 "8 Bit checksum for protection of frame contents";
CM_ BO_ 1121 "Randomly defined CAN frame";
CM_ SG_ 1121 checksum_9_8 "8 Bit checksum for protection of frame contents";
CM_ BO_ 1648 "Randomly defined CAN frame";
CM_ SG_ 1648 checksum_1_8 "8 Bit checksum for protection of frame contents";
CM_ BO_ 627 "Randomly defined CAN frame";
CM_ SG_ 627 checksum_9_8 "8 Bit checksum for protection of frame contents";
CM_ BO_ 1120 "Randomly defined CAN frame";
CM_ SG_ 1120 checksum_17_8 "8 Bit checksum for protection of frame contents";
CM_ BO_ 973 "Randomly defined CAN frame";
CM_ SG_ 973 checksum_1_8 "8 Bit checksum for protection of frame contents";
CM_ BO_ 1362 "Randomly defined CAN frame";
CM_ SG_ 1362 checksum_33_8 "8 Bit checksum for protection of frame contents";
CM_ BO_ 897 "Randomly defined CAN frame";
CM_ SG_ 897 checksum_49_8 "8 Bit checksum for protection of frame contents";
BA_DEF_ "Author" STRING;
BA_DEF_ BO_ "frameSendMode" ENUM  "regular","event","mixed";
BA_DEF_ BO_ "sendPeriod" INT 5 10000;
BA_DEF_ BO_ "crcStartValue" INT 1 255;
BA_DEF_ BO_ "eventMinDistance" INT 5 10000;
BA_DEF_ SG_ "initialValue" FLOAT -1e38 1e38;
BA_DEF_DEF_ "Author" "http://sourceforge.net/projects/comframe/";
BA_DEF_DEF_ "frameSendMode" "regular";
BA_DEF_DEF_ "sendPeriod" 10;
BA_DEF_DEF_ "crcStartValue" 1;
BA_DEF_DEF_ "eventMinDistance" 10;
BA_DEF_DEF_ "initialValue" 0.0;
BA_ "frameSendMode" BO_ 1676 2;
BA_ "sendPeriod" BO_ 1676 1000;
BA_ "eventMinDistance" BO_ 1676 100;
BA_ "crcStartValue" BO_ 1676 237;
BA_ "initialValue" SG_ 1676 sig_22_19 61299.076601683795;
BA_ "initialValue" SG_ 1676 sig_6_8 1373.772233983162;
BA_ "initialValue" SG_ 1676 sig_10_4 3.837722339831625E-5;
BA_ "initialValue" SG_ 1676 sig_11_4 3837.7223398316205;
BA_ "initialValue" SG_ 1676 sig_35_4 0.008000000000000002;
BA_ "initialValue" SG_ 1676 sig_54_7 68000.0;
BA_ "frameSendMode" BO_ 1012 2;
BA_ "sendPeriod" BO_ 1012 500;
BA_ "eventMinDistance" BO_ 1012 500;
BA_ "crcStartValue" BO_ 1012 237;
BA_ "initialValue" SG_ 1012 sig_8_14 -5316.0;
BA_ "initialValue" SG_ 1012 sig_9_7 0.0886227766016838;
BA_ "initialValue" SG_ 1012 sig_24_3 -2.0;
BA_ "crcStartValue" BO_ 1491 33;
BA_ "initialValue" SG_ 1491 sig_4_18 231022.0;
BA_ "initialValue" SG_ 1491 sig_1_3 -2.0;
BA_ "initialValue" SG_ 1491 sig_22_2 3.0;
BA_ "initialValue" SG_ 1491 sig_41_7 84.0;
BA_ "initialValue" SG_ 1491 sig_39_6 0.0029000000000000015;
BA_ "initialValue" SG_ 1491 sig_32_2 -1.0;
BA_ "frameSendMode" BO_ 1536 2;
BA_ "sendPeriod" BO_ 1536 1000;
BA_ "eventMinDistance" BO_ 1536 100;
BA_ "crcStartValue" BO_ 1536 97;
BA_ "initialValue" SG_ 1536 sig_17_10 23.0;
BA_ "sendPeriod" BO_ 499 1000;
BA_ "crcStartValue" BO_ 499 25;
BA_ "initialValue" SG_ 499 sig_1_15 8321.0;
BA_ "initialValue" SG_ 499 sig_0_1 1.0;
BA_ "initialValue" SG_ 499 sig_28_5 19.0;
BA_ "initialValue" SG_ 499 sig_31_3 4.0;
BA_ "frameSendMode" BO_ 621 2;
BA_ "sendPeriod" BO_ 621 10000;
BA_ "eventMinDistance" BO_ 621 1000;
BA_ "crcStartValue" BO_ 621 33;
BA_ "initialValue" SG_ 621 sig_3_14 0.0030190000000000017;
BA_ "initialValue" SG_ 621 sig_7_4 5.0;
BA_ "initialValue" SG_ 621 sig_20_5 10.0;
BA_ "initialValue" SG_ 621 sig_21_1 1.0;
BA_ "sendPeriod" BO_ 538 20;
BA_ "crcStartValue" BO_ 538 85;
BA_ "initialValue" SG_ 538 sig_6_15 28955.776601683792;
BA_ "initialValue" SG_ 538 sig_51_9 0.003070000000000002;
BA_ "initialValue" SG_ 538 sig_29_13 1132.0;
BA_ "initialValue" SG_ 538 sig_31_2 -2.0;
BA_ "initialValue" SG_ 538 sig_44_9 1.1477223398316236E-5;
BA_ "initialValue" SG_ 538 sig_58_3 -3.0;
BA_ "sendPeriod" BO_ 1384 1000;
BA_ "crcStartValue" BO_ 1384 55;
BA_ "initialValue" SG_ 1384 sig_0_7 0.014622776601683787;
BA_ "initialValue" SG_ 1384 sig_27_19 15349.7;
BA_ "initialValue" SG_ 1384 sig_16_7 15.0;
BA_ "initialValue" SG_ 1384 sig_28_4 1.4162277660168386E-5;
BA_ "initialValue" SG_ 1384 sig_48_8 0.4900000000000001;
BA_ "frameSendMode" BO_ 993 2;
BA_ "sendPeriod" BO_ 993 500;
BA_ "eventMinDistance" BO_ 993 100;
BA_ "crcStartValue" BO_ 993 212;
BA_ "initialValue" SG_ 993 sig_0_18 146831.0;
BA_ "initialValue" SG_ 993 sig_18_6 54622.77660168379;
BA_ "initialValue" SG_ 993 sig_39_16 15171.0;
BA_ "initialValue" SG_ 993 sig_48_8 0.02506227766016839;
BA_ "frameSendMode" BO_ 21 2;
BA_ "sendPeriod" BO_ 21 1000;
BA_ "eventMinDistance" BO_ 21 50;
BA_ "crcStartValue" BO_ 21 155;
BA_ "initialValue" SG_ 21 sig_4_12 36882.77660168379;
BA_ "initialValue" SG_ 21 sig_0_4 -300.0;
BA_ "initialValue" SG_ 21 sig_30_7 48.0;
BA_ "initialValue" SG_ 21 sig_17_7 52.0;
BA_ "initialValue" SG_ 21 sig_33_5 -0.00466227766016838;
BA_ "initialValue" SG_ 21 sig_32_1 1.0;
BA_ "sendPeriod" BO_ 1210 500;
BA_ "crcStartValue" BO_ 1210 226;
BA_ "initialValue" SG_ 1210 sig_34_14 -81232.77660168378;
BA_ "initialValue" SG_ 1210 sig_13_2 2.0;
BA_ "initialValue" SG_ 1210 sig_8_3 -2.0;
BA_ "initialValue" SG_ 1210 sig_15_2 1.0;
BA_ "initialValue" SG_ 1210 sig_18_12 2.4920000000000022E-5;
BA_ "initialValue" SG_ 1210 sig_32_1 1.0;
BA_ "initialValue" SG_ 1210 sig_52_4 -2162.2776601683795;
BA_ "sendPeriod" BO_ 566 20;
BA_ "crcStartValue" BO_ 566 27;
BA_ "initialValue" SG_ 566 sig_6_14 8507.0;
BA_ "initialValue" SG_ 566 sig_7_1 1.0;
BA_ "initialValue" SG_ 566 sig_31_16 1098.7766016837923;
BA_ "initialValue" SG_ 566 sig_47_8 204.0;
BA_ "frameSendMode" BO_ 409 2;
BA_ "sendPeriod" BO_ 409 1000;
BA_ "eventMinDistance" BO_ 409 500;
BA_ "crcStartValue" BO_ 409 106;
BA_ "initialValue" SG_ 409 sig_10_8 -7900.0;
BA_ "initialValue" SG_ 409 sig_0_10 481.0;
BA_ "initialValue" SG_ 409 sig_18_4 10.0;
BA_ "initialValue" SG_ 409 sig_22_2 -2.0;
BA_ "initialValue" SG_ 409 sig_37_14 -5556.0;
BA_ "initialValue" SG_ 409 sig_32_3 -1.0;
BA_ "initialValue" SG_ 409 sig_35_2 1.0;
BA_ "initialValue" SG_ 409 sig_52_4 -0.05000000000000001;
BA_ "sendPeriod" BO_ 810 20;
BA_ "crcStartValue" BO_ 810 222;
BA_ "initialValue" SG_ 810 sig_2_6 40.0;
BA_ "initialValue" SG_ 810 sig_0_2 -2.0;
BA_ "initialValue" SG_ 810 sig_21_6 7.0;
BA_ "initialValue" SG_ 810 sig_23_2 -1.0;
BA_ "sendPeriod" BO_ 1001 20;
BA_ "crcStartValue" BO_ 1001 156;
BA_ "initialValue" SG_ 1001 sig_3_12 -2.161277660168379;
BA_ "initialValue" SG_ 1001 sig_2_4 8.162277660168382E-6;
BA_ "initialValue" SG_ 1001 sig_31_13 2471.0;
BA_ "initialValue" SG_ 1001 sig_32_1 1.0;
BA_ "sendPeriod" BO_ 1148 500;
BA_ "crcStartValue" BO_ 1148 51;
BA_ "initialValue" SG_ 1148 sig_37_16 723.2377660168381;
BA_ "initialValue" SG_ 1148 sig_15_14 1706.027766016838;
BA_ "initialValue" SG_ 1148 sig_9_6 43622.77660168379;
BA_ "initialValue" SG_ 1148 sig_8_1 1.0;
BA_ "initialValue" SG_ 1148 sig_29_3 1.0;
BA_ "initialValue" SG_ 1148 sig_38_2 1.0;
BA_ "initialValue" SG_ 1148 sig_49_5 -1662.2776601683795;
BA_ "sendPeriod" BO_ 1934 25;
BA_ "crcStartValue" BO_ 1934 102;
BA_ "initialValue" SG_ 1934 sig_5_13 -2.57277660168377E-6;
BA_ "initialValue" SG_ 1934 sig_0_4 3.0;
BA_ "initialValue" SG_ 1934 sig_21_4 1.6162277660168386E-4;
BA_ "initialValue" SG_ 1934 sig_22_2 1.0;
BA_ "initialValue" SG_ 1934 sig_32_15 4.65247766016838;
BA_ "initialValue" SG_ 1934 sig_47_1 1.0;
BA_ "sendPeriod" BO_ 1238 5;
BA_ "crcStartValue" BO_ 1238 38;
BA_ "initialValue" SG_ 1238 sig_1_16 0.6224000000000003;
BA_ "initialValue" SG_ 1238 sig_18_14 -47382.77660168379;
BA_ "sendPeriod" BO_ 1602 50;
BA_ "crcStartValue" BO_ 1602 43;
BA_ "initialValue" SG_ 1602 sig_6_7 55.0;
BA_ "initialValue" SG_ 1602 sig_7_1 1.0;
BA_ "initialValue" SG_ 1602 sig_33_20 0.0061015276601683825;
BA_ "initialValue" SG_ 1602 sig_22_10 8.01227766016838;
BA_ "initialValue" SG_ 1602 sig_21_5 -0.00446227766016838;
BA_ "initialValue" SG_ 1602 sig_34_4 6.0;
BA_ "initialValue" SG_ 1602 sig_56_6 -1.662277660168378E-6;
BA_ "sendPeriod" BO_ 113 20;
BA_ "crcStartValue" BO_ 113 88;
BA_ "initialValue" SG_ 113 sig_2_10 992.0;
BA_ "initialValue" SG_ 113 sig_0_2 1.0;
BA_ "initialValue" SG_ 113 sig_15_4 13.0;
BA_ "initialValue" SG_ 113 sig_22_5 8.0;
BA_ "initialValue" SG_ 113 sig_32_9 -5.552277660168381E-4;
BA_ "initialValue" SG_ 113 sig_37_5 -16.0;
BA_ "initialValue" SG_ 113 sig_49_6 -0.002700000000000001;
BA_ "initialValue" SG_ 113 sig_55_1 1.0;
BA_ "sendPeriod" BO_ 1629 500;
BA_ "crcStartValue" BO_ 1629 26;
BA_ "initialValue" SG_ 1629 sig_17_14 -202.0;
BA_ "initialValue" SG_ 1629 sig_3_15 -2.801677660168379E-4;
BA_ "initialValue" SG_ 1629 sig_7_2 -1.0;
BA_ "initialValue" SG_ 1629 sig_5_2 1.0;
BA_ "initialValue" SG_ 1629 sig_19_2 2.0;
BA_ "initialValue" SG_ 1629 sig_32_3 3.0;
BA_ "initialValue" SG_ 1629 sig_35_1 1.0;
BA_ "initialValue" SG_ 1629 sig_40_14 2707.0;
BA_ "sendPeriod" BO_ 1928 500;
BA_ "crcStartValue" BO_ 1928 102;
BA_ "initialValue" SG_ 1928 sig_12_3 3.0;
BA_ "initialValue" SG_ 1928 sig_6_9 451.0;
BA_ "initialValue" SG_ 1928 sig_17_9 189.0;
BA_ "initialValue" SG_ 1928 sig_8_5 0.37622776601683794;
BA_ "initialValue" SG_ 1928 sig_9_1 1.0;
BA_ "initialValue" SG_ 1928 sig_19_2 2.0;
BA_ "initialValue" SG_ 1928 sig_24_1 1.0;
BA_ "initialValue" SG_ 1928 sig_47_6 0.0586227766016838;
BA_ "initialValue" SG_ 1928 sig_41_2 -2.0;
BA_ "sendPeriod" BO_ 1256 10000;
BA_ "crcStartValue" BO_ 1256 28;
BA_ "initialValue" SG_ 1256 sig_5_20 1045637.0;
BA_ "initialValue" SG_ 1256 sig_6_2 3.0;
BA_ "initialValue" SG_ 1256 sig_16_2 3.0;
BA_ "initialValue" SG_ 1256 sig_35_12 3189.0;
BA_ "initialValue" SG_ 1256 sig_39_4 1.3;
BA_ "sendPeriod" BO_ 1538 100;
BA_ "crcStartValue" BO_ 1538 67;
BA_ "initialValue" SG_ 1538 sig_2_32 -0.2648218852168379;
BA_ "initialValue" SG_ 1538 sig_1_2 1.0;
BA_ "initialValue" SG_ 1538 sig_39_6 0.0019000000000000009;
BA_ "initialValue" SG_ 1538 sig_46_7 56.0;
BA_ "initialValue" SG_ 1538 sig_63_7 7.5377223398316285E-6;
BA_ "initialValue" SG_ 1538 sig_56_1 1.0;
BA_ "sendPeriod" BO_ 1852 5;
BA_ "crcStartValue" BO_ 1852 79;
BA_ "initialValue" SG_ 1852 sig_14_9 0.26200000000000007;
BA_ "initialValue" SG_ 1852 sig_6_6 0.416227766016838;
BA_ "initialValue" SG_ 1852 sig_0_1 1.0;
BA_ "initialValue" SG_ 1852 sig_16_6 1400.0;
BA_ "initialValue" SG_ 1852 sig_26_11 -5.877223398316235E-6;
BA_ "initialValue" SG_ 1852 sig_30_4 8.0;
BA_ "initialValue" SG_ 1852 sig_48_13 6860.0;
BA_ "sendPeriod" BO_ 1146 20;
BA_ "crcStartValue" BO_ 1146 152;
BA_ "initialValue" SG_ 1146 sig_0_11 1180.0;
BA_ "initialValue" SG_ 1146 sig_11_5 16.0;
BA_ "initialValue" SG_ 1146 sig_30_7 82.0;
BA_ "initialValue" SG_ 1146 sig_31_1 1.0;
BA_ "sendPeriod" BO_ 1025 10000;
BA_ "crcStartValue" BO_ 1025 249;
BA_ "initialValue" SG_ 1025 sig_1_15 3861.0;
BA_ "initialValue" SG_ 1025 sig_0_1 1.0;
BA_ "initialValue" SG_ 1025 sig_25_13 1.3930000000000012E-5;
BA_ "initialValue" SG_ 1025 sig_24_1 1.0;
BA_ "initialValue" SG_ 1025 sig_38_2 3.0;
BA_ "crcStartValue" BO_ 1610 200;
BA_ "initialValue" SG_ 1610 sig_5_6 -31.0;
BA_ "initialValue" SG_ 1610 sig_6_2 2.0;
BA_ "initialValue" SG_ 1610 sig_17_14 13608.0;
BA_ "sendPeriod" BO_ 1315 50;
BA_ "crcStartValue" BO_ 1315 223;
BA_ "initialValue" SG_ 1315 sig_18_31 5.276552298316244E-4;
BA_ "initialValue" SG_ 1315 sig_13_5 34622.77660168379;
BA_ "initialValue" SG_ 1315 sig_8_5 4.362277660168379;
BA_ "initialValue" SG_ 1315 sig_49_5 24622.776601683792;
BA_ "initialValue" SG_ 1315 sig_54_2 1.0;
BA_ "sendPeriod" BO_ 900 20;
BA_ "crcStartValue" BO_ 900 31;
BA_ "initialValue" SG_ 900 sig_11_11 8.660000000000006E-4;
BA_ "initialValue" SG_ 900 sig_7_8 2.2237722339831637E-5;
BA_ "initialValue" SG_ 900 sig_9_4 70000.0;
BA_ "initialValue" SG_ 900 sig_34_16 43.09500000000001;
BA_ "initialValue" SG_ 900 sig_35_4 5.0;
BA_ "initialValue" SG_ 900 sig_48_3 6.0;
BA_ "sendPeriod" BO_ 29 5;
BA_ "crcStartValue" BO_ 29 234;
BA_ "initialValue" SG_ 29 sig_0_8 -1.4962277660168382;
BA_ "initialValue" SG_ 29 sig_18_2 -1.0;
BA_ "initialValue" SG_ 29 sig_16_2 -1.0;
BA_ "initialValue" SG_ 29 sig_21_21 1.1219923398316234;
BA_ "initialValue" SG_ 29 sig_51_4 -1.0;
BA_ "initialValue" SG_ 29 sig_43_5 2.862277660168379E-6;
BA_ "initialValue" SG_ 29 sig_42_1 1.0;
BA_ "frameSendMode" BO_ 171 2;
BA_ "sendPeriod" BO_ 171 500;
BA_ "eventMinDistance" BO_ 171 500;
BA_ "crcStartValue" BO_ 171 73;
BA_ "initialValue" SG_ 171 sig_0_8 0.12400000000000003;
BA_ "initialValue" SG_ 171 sig_21_16 4.3066776601683804E-4;
BA_ "initialValue" SG_ 171 sig_16_5 13.0;
BA_ "sendPeriod" BO_ 240 1000;
BA_ "crcStartValue" BO_ 240 211;
BA_ "initialValue" SG_ 240 sig_15_17 -36.186776601683796;
BA_ "initialValue" SG_ 240 sig_8_7 5000.0;
BA_ "initialValue" SG_ 240 sig_35_5 -126.22776601683796;
BA_ "sendPeriod" BO_ 726 50;
BA_ "crcStartValue" BO_ 726 70;
BA_ "initialValue" SG_ 726 sig_14_25 11.578770000000008;
BA_ "initialValue" SG_ 726 sig_33_4 0.08000000000000002;
BA_ "initialValue" SG_ 726 sig_37_1 1.0;
BA_ "initialValue" SG_ 726 sig_63_8 15062.27766016838;
BA_ "frameSendMode" BO_ 245 2;
BA_ "sendPeriod" BO_ 245 10000;
BA_ "eventMinDistance" BO_ 245 50;
BA_ "crcStartValue" BO_ 245 85;
BA_ "initialValue" SG_ 245 sig_4_18 115.13822339831623;
BA_ "initialValue" SG_ 245 sig_18_2 -1.0;
BA_ "frameSendMode" BO_ 1965 2;
BA_ "sendPeriod" BO_ 1965 10000;
BA_ "eventMinDistance" BO_ 1965 100;
BA_ "crcStartValue" BO_ 1965 205;
BA_ "initialValue" SG_ 1965 sig_5_18 0.019970877660168394;
BA_ "initialValue" SG_ 1965 sig_7_2 1.0;
BA_ "initialValue" SG_ 1965 sig_16_4 -1.6227766016837776E-6;
BA_ "initialValue" SG_ 1965 sig_30_18 55438.0;
BA_ "initialValue" SG_ 1965 sig_44_5 4.862277660168379;
BA_ "sendPeriod" BO_ 178 100;
BA_ "crcStartValue" BO_ 178 140;
BA_ "initialValue" SG_ 178 sig_7_10 3.580000000000003E-5;
BA_ "initialValue" SG_ 178 sig_3_4 1.0;
BA_ "initialValue" SG_ 178 sig_0_3 2.0;
BA_ "initialValue" SG_ 178 sig_20_20 126373.17660168381;
BA_ "initialValue" SG_ 178 sig_18_2 2.0;
BA_ "initialValue" SG_ 178 sig_19_1 1.0;
BA_ "sendPeriod" BO_ 2031 1000;
BA_ "crcStartValue" BO_ 2031 229;
BA_ "initialValue" SG_ 2031 sig_7_9 2.0;
BA_ "initialValue" SG_ 2031 sig_14_6 3.8622776601683796E-5;
BA_ "initialValue" SG_ 2031 sig_8_1 1.0;
BA_ "initialValue" SG_ 2031 sig_24_9 119.22776601683796;
BA_ "initialValue" SG_ 2031 sig_31_7 68000.0;
BA_ "initialValue" SG_ 2031 sig_47_11 269.0;
BA_ "initialValue" SG_ 2031 sig_50_3 1.0;
BA_ "frameSendMode" BO_ 1393 2;
BA_ "sendPeriod" BO_ 1393 500;
BA_ "eventMinDistance" BO_ 1393 50;
BA_ "crcStartValue" BO_ 1393 45;
BA_ "initialValue" SG_ 1393 sig_10_13 0.009913277660168383;
BA_ "initialValue" SG_ 1393 sig_1_9 410.0;
BA_ "initialValue" SG_ 1393 sig_38_7 0.055000000000000014;
BA_ "sendPeriod" BO_ 1338 1000;
BA_ "crcStartValue" BO_ 1338 50;
BA_ "initialValue" SG_ 1338 sig_3_4 0.10000000000000002;
BA_ "initialValue" SG_ 1338 sig_7_4 -0.0016227766016837855;
BA_ "initialValue" SG_ 1338 sig_23_8 23562.27766016838;
BA_ "frameSendMode" BO_ 1935 2;
BA_ "sendPeriod" BO_ 1935 1000;
BA_ "eventMinDistance" BO_ 1935 100;
BA_ "crcStartValue" BO_ 1935 52;
BA_ "initialValue" SG_ 1935 sig_0_8 119.0;
BA_ "initialValue" SG_ 1935 sig_10_22 1.890103398316241E-5;
BA_ "initialValue" SG_ 1935 sig_8_2 1.0;
BA_ "initialValue" SG_ 1935 sig_45_20 21366.176601683794;
BA_ "initialValue" SG_ 1935 sig_47_2 -2.0;
BA_ "initialValue" SG_ 1935 sig_56_2 1.0;
BA_ "sendPeriod" BO_ 1478 10000;
BA_ "crcStartValue" BO_ 1478 163;
BA_ "initialValue" SG_ 1478 sig_1_16 -1.6281776601683782E-4;
BA_ "initialValue" SG_ 1478 sig_43_12 -1696.0;
BA_ "initialValue" SG_ 1478 sig_36_6 -0.05622776601683788;
BA_ "initialValue" SG_ 1478 sig_42_1 1.0;
BA_ "frameSendMode" BO_ 1500 2;
BA_ "sendPeriod" BO_ 1500 10000;
BA_ "eventMinDistance" BO_ 1500 100;
BA_ "crcStartValue" BO_ 1500 189;
BA_ "initialValue" SG_ 1500 sig_14_14 7130.0;
BA_ "initialValue" SG_ 1500 sig_6_8 141622.77660168378;
BA_ "sendPeriod" BO_ 1416 5;
BA_ "initialValue" SG_ 1416 sig_15_6 1.037722339831623E-5;
BA_ "initialValue" SG_ 1416 sig_47_11 -0.18400000000000005;
BA_ "initialValue" SG_ 1416 sig_18_8 192.0;
BA_ "initialValue" SG_ 1416 sig_22_3 6.0;
BA_ "initialValue" SG_ 1416 sig_23_1 1.0;
BA_ "initialValue" SG_ 1416 sig_26_11 -583.0;
BA_ "initialValue" SG_ 1416 sig_52_13 7301.0;
BA_ "sendPeriod" BO_ 2033 25;
BA_ "crcStartValue" BO_ 2033 4;
BA_ "initialValue" SG_ 2033 sig_5_5 -27622.776601683792;
BA_ "initialValue" SG_ 2033 sig_7_2 1.0;
BA_ "initialValue" SG_ 2033 sig_18_21 2.678380000000003E-5;
BA_ "initialValue" SG_ 2033 sig_16_2 1.0;
BA_ "initialValue" SG_ 2033 sig_43_9 3.950000000000002E-4;
BA_ "initialValue" SG_ 2033 sig_40_2 -2.0;
BA_ "initialValue" SG_ 2033 sig_55_4 9.000000000000005E-6;
BA_ "sendPeriod" BO_ 1058 500;
BA_ "crcStartValue" BO_ 1058 174;
BA_ "initialValue" SG_ 1058 sig_13_16 28640.0;
BA_ "initialValue" SG_ 1058 sig_28_4 0.030000000000000006;
BA_ "initialValue" SG_ 1058 sig_29_1 1.0;
BA_ "sendPeriod" BO_ 223 25;
BA_ "crcStartValue" BO_ 223 69;
BA_ "initialValue" SG_ 223 sig_4_21 -7.890610000000005;
BA_ "initialValue" SG_ 223 sig_0_4 -2.162277660168379E-4;
BA_ "initialValue" SG_ 223 sig_34_10 755.0;
BA_ "initialValue" SG_ 223 sig_29_5 11.0;
BA_ "initialValue" SG_ 223 sig_25_4 0.0010162277660168383;
BA_ "initialValue" SG_ 223 sig_47_4 -0.0916227766016838;
BA_ "frameSendMode" BO_ 950 2;
BA_ "sendPeriod" BO_ 950 1000;
BA_ "eventMinDistance" BO_ 950 1000;
BA_ "crcStartValue" BO_ 950 147;
BA_ "initialValue" SG_ 950 sig_12_13 -7.810000000000006E-5;
BA_ "initialValue" SG_ 950 sig_1_7 0.007337722339831624;
BA_ "initialValue" SG_ 950 sig_0_3 2.0;
BA_ "initialValue" SG_ 950 sig_25_7 -2.3000000000000003;
BA_ "initialValue" SG_ 950 sig_44_7 40.0;
BA_ "initialValue" SG_ 950 sig_48_5 -0.003000000000000001;
BA_ "initialValue" SG_ 950 sig_45_3 2.0;
BA_ "initialValue" SG_ 950 sig_53_1 1.0;
BA_ "initialValue" SG_ 950 sig_61_5 29.0;
BA_ "initialValue" SG_ 950 sig_56_1 1.0;
BA_ "frameSendMode" BO_ 734 2;
BA_ "sendPeriod" BO_ 734 500;
BA_ "eventMinDistance" BO_ 734 100;
BA_ "crcStartValue" BO_ 734 109;
BA_ "initialValue" SG_ 734 sig_0_1 1.0;
BA_ "initialValue" SG_ 734 sig_7_3 4.0;
BA_ "initialValue" SG_ 734 sig_20_9 302.0;
BA_ "initialValue" SG_ 734 sig_15_6 -20.0;
BA_ "initialValue" SG_ 734 sig_8_2 -1.0;
BA_ "initialValue" SG_ 734 sig_16_3 -4.0;
BA_ "initialValue" SG_ 734 sig_29_3 2.0;
BA_ "initialValue" SG_ 734 sig_44_18 7.777877660168382;
BA_ "initialValue" SG_ 734 sig_47_3 -1.0;
BA_ "initialValue" SG_ 734 sig_58_3 6.0;
BA_ "frameSendMode" BO_ 971 2;
BA_ "sendPeriod" BO_ 971 1000;
BA_ "eventMinDistance" BO_ 971 1000;
BA_ "crcStartValue" BO_ 971 33;
BA_ "initialValue" SG_ 971 sig_2_10 2320.0;
BA_ "initialValue" SG_ 971 sig_6_4 1.0837722339831629E-5;
BA_ "initialValue" SG_ 971 sig_7_1 1.0;
BA_ "initialValue" SG_ 971 sig_25_8 2.377223398316234E-7;
BA_ "initialValue" SG_ 971 sig_24_1 1.0;
BA_ "initialValue" SG_ 971 sig_33_9 11.0;
BA_ "initialValue" SG_ 971 sig_47_9 7.0;
BA_ "initialValue" SG_ 971 sig_42_5 4.000000000000002E-4;
BA_ "sendPeriod" BO_ 1565 50;
BA_ "crcStartValue" BO_ 1565 52;
BA_ "initialValue" SG_ 1565 sig_17_1 1.0;
BA_ "initialValue" SG_ 1565 sig_1_15 3.0630000000000006;
BA_ "initialValue" SG_ 1565 sig_0_1 1.0;
BA_ "initialValue" SG_ 1565 sig_28_17 -1612.0223398316207;
BA_ "initialValue" SG_ 1565 sig_18_10 229.0;
BA_ "initialValue" SG_ 1565 sig_45_3 2.0;
BA_ "initialValue" SG_ 1565 sig_59_4 -1.1622776601683785E-4;
BA_ "initialValue" SG_ 1565 sig_56_3 6.0;
BA_ "sendPeriod" BO_ 1815 500;
BA_ "crcStartValue" BO_ 1815 116;
BA_ "initialValue" SG_ 1815 sig_3_16 -1.0552233983162118;
BA_ "initialValue" SG_ 1815 sig_22_8 -0.7100000000000002;
BA_ "initialValue" SG_ 1815 sig_19_3 3.0;
BA_ "initialValue" SG_ 1815 sig_40_15 10693.0;
BA_ "initialValue" SG_ 1815 sig_55_1 1.0;
BA_ "frameSendMode" BO_ 824 2;
BA_ "sendPeriod" BO_ 824 500;
BA_ "eventMinDistance" BO_ 824 50;
BA_ "crcStartValue" BO_ 824 175;
BA_ "initialValue" SG_ 824 sig_14_38 193.0737894073164;
BA_ "initialValue" SG_ 824 sig_5_5 4.0;
BA_ "initialValue" SG_ 824 sig_40_1 1.0;
BA_ "initialValue" SG_ 824 sig_62_7 1.400000000000001E-6;
BA_ "initialValue" SG_ 824 sig_63_1 1.0;
BA_ "frameSendMode" BO_ 445 2;
BA_ "sendPeriod" BO_ 445 10000;
BA_ "eventMinDistance" BO_ 445 1000;
BA_ "crcStartValue" BO_ 445 133;
BA_ "initialValue" SG_ 445 sig_4_10 225.0;
BA_ "initialValue" SG_ 445 sig_0_3 3.0;
BA_ "initialValue" SG_ 445 sig_33_12 13110.0;
BA_ "initialValue" SG_ 445 sig_24_9 -0.02562277660168379;
BA_ "crcStartValue" BO_ 583 176;
BA_ "initialValue" SG_ 583 sig_11_14 -0.0014647223398316232;
BA_ "initialValue" SG_ 583 sig_7_3 2.0;
BA_ "initialValue" SG_ 583 sig_1_2 -2.0;
BA_ "initialValue" SG_ 583 sig_31_7 -256.22776601683796;
BA_ "initialValue" SG_ 583 sig_47_11 368.0;
BA_ "initialValue" SG_ 583 sig_51_3 1.0;
BA_ "crcStartValue" BO_ 1699 22;
BA_ "initialValue" SG_ 1699 sig_17_6 7.762277660168383E-4;
BA_ "initialValue" SG_ 1699 sig_1_11 -177.0;
BA_ "initialValue" SG_ 1699 sig_7_6 46.0;
BA_ "initialValue" SG_ 1699 sig_22_5 27.0;
BA_ "initialValue" SG_ 1699 sig_26_10 -1.022277660168378E-5;
BA_ "initialValue" SG_ 1699 sig_32_1 1.0;
BA_ "frameSendMode" BO_ 551 2;
BA_ "sendPeriod" BO_ 551 1000;
BA_ "eventMinDistance" BO_ 551 100;
BA_ "crcStartValue" BO_ 551 210;
BA_ "initialValue" SG_ 551 sig_22_9 314.0;
BA_ "initialValue" SG_ 551 sig_17_5 -0.0020000000000000005;
BA_ "initialValue" SG_ 551 sig_10_7 56.0;
BA_ "initialValue" SG_ 551 sig_32_7 42622.77660168379;
BA_ "initialValue" SG_ 551 sig_39_1 1.0;
BA_ "sendPeriod" BO_ 8 10000;
BA_ "crcStartValue" BO_ 8 173;
BA_ "initialValue" SG_ 8 sig_3_21 8.90658233983163E-4;
BA_ "initialValue" SG_ 8 sig_4_3 3.0;
BA_ "initialValue" SG_ 8 sig_7_1 1.0;
BA_ "initialValue" SG_ 8 sig_25_6 7.662277660168382E-6;
BA_ "initialValue" SG_ 8 sig_33_4 0.1116227766016838;
BA_ "initialValue" SG_ 8 sig_39_3 -2.0;
BA_ "initialValue" SG_ 8 sig_52_13 141.62776601683794;
BA_ "initialValue" SG_ 8 sig_54_2 -2.0;
BA_ "frameSendMode" BO_ 1698 2;
BA_ "sendPeriod" BO_ 1698 1000;
BA_ "eventMinDistance" BO_ 1698 1000;
BA_ "crcStartValue" BO_ 1698 97;
BA_ "initialValue" SG_ 1698 sig_7_4 -71.6227766016838;
BA_ "initialValue" SG_ 1698 sig_23_31 -0.014552596983162358;
BA_ "initialValue" SG_ 1698 sig_55_7 490.0;
BA_ "initialValue" SG_ 1698 sig_40_1 1.0;
BA_ "crcStartValue" BO_ 840 7;
BA_ "initialValue" SG_ 840 sig_7_19 116313.0;
BA_ "initialValue" SG_ 840 sig_20_5 -0.00456227766016838;
BA_ "sendPeriod" BO_ 899 500;
BA_ "crcStartValue" BO_ 899 170;
BA_ "initialValue" SG_ 899 sig_24_3 2.0;
BA_ "initialValue" SG_ 899 sig_9_7 -2.262277660168379E-5;
BA_ "initialValue" SG_ 899 sig_23_14 11685.0;
BA_ "initialValue" SG_ 899 sig_41_16 -58.687766016837884;
BA_ "initialValue" SG_ 899 sig_33_5 5.0;
BA_ "initialValue" SG_ 899 sig_45_3 -2.0;
BA_ "initialValue" SG_ 899 sig_42_3 1.0;
BA_ "sendPeriod" BO_ 148 20;
BA_ "crcStartValue" BO_ 148 108;
BA_ "initialValue" SG_ 148 sig_9_26 27509.221000000005;
BA_ "frameSendMode" BO_ 1854 2;
BA_ "sendPeriod" BO_ 1854 500;
BA_ "eventMinDistance" BO_ 1854 50;
BA_ "crcStartValue" BO_ 1854 165;
BA_ "initialValue" SG_ 1854 sig_2_6 4362.27766016838;
BA_ "initialValue" SG_ 1854 sig_1_6 -0.04062277660168379;
BA_ "initialValue" SG_ 1854 sig_32_4 6162.27766016838;
BA_ "initialValue" SG_ 1854 sig_40_11 1.0317722339831632E-5;
BA_ "initialValue" SG_ 1854 sig_55_5 -13.0;
BA_ "crcStartValue" BO_ 1142 135;
BA_ "initialValue" SG_ 1142 sig_7_7 -49.0;
BA_ "initialValue" SG_ 1142 sig_0_1 1.0;
BA_ "initialValue" SG_ 1142 sig_18_11 512.0;
BA_ "initialValue" SG_ 1142 sig_31_3 -4.0;
BA_ "initialValue" SG_ 1142 sig_34_7 -0.002262277660168379;
BA_ "initialValue" SG_ 1142 sig_39_5 -900.0;
BA_ "initialValue" SG_ 1142 sig_43_3 -1.0;
BA_ "initialValue" SG_ 1142 sig_40_1 1.0;
BA_ "sendPeriod" BO_ 1007 10000;
BA_ "crcStartValue" BO_ 1007 48;
BA_ "initialValue" SG_ 1007 sig_9_12 -990.0;
BA_ "initialValue" SG_ 1007 sig_7_2 1.0;
BA_ "initialValue" SG_ 1007 sig_15_5 900.0;
BA_ "initialValue" SG_ 1007 sig_10_1 1.0;
BA_ "initialValue" SG_ 1007 sig_25_16 18439.0;
BA_ "initialValue" SG_ 1007 sig_41_10 35.42277660168379;
BA_ "crcStartValue" BO_ 1613 45;
BA_ "initialValue" SG_ 1613 sig_2_17 -64995.0;
BA_ "initialValue" SG_ 1613 sig_7_5 18.622776601683793;
BA_ "initialValue" SG_ 1613 sig_16_2 -2.0;
BA_ "initialValue" SG_ 1613 sig_29_12 4.7432776601683804E-4;
BA_ "initialValue" SG_ 1613 sig_31_2 3.0;
BA_ "initialValue" SG_ 1613 sig_33_2 -1.0;
BA_ "sendPeriod" BO_ 1474 5;
BA_ "crcStartValue" BO_ 1474 225;
BA_ "initialValue" SG_ 1474 sig_55_8 -7.600000000000005E-4;
BA_ "initialValue" SG_ 1474 sig_13_19 1967.9;
BA_ "initialValue" SG_ 1474 sig_37_9 2.8400000000000023E-5;
BA_ "initialValue" SG_ 1474 sig_24_2 -1.0;
BA_ "initialValue" SG_ 1474 sig_25_2 2.0;
BA_ "initialValue" SG_ 1474 sig_38_1 1.0;
BA_ "initialValue" SG_ 1474 sig_44_3 1.0;
BA_ "initialValue" SG_ 1474 sig_41_1 1.0;
BA_ "initialValue" SG_ 1474 sig_56_7 -0.0013377223398316229;
BA_ "initialValue" SG_ 1474 sig_63_1 1.0;
BA_ "sendPeriod" BO_ 1762 5;
BA_ "crcStartValue" BO_ 1762 94;
BA_ "initialValue" SG_ 1762 sig_12_13 -2.8042776601683792E-5;
BA_ "initialValue" SG_ 1762 sig_5_5 6.0;
BA_ "initialValue" SG_ 1762 sig_26_8 114.0;
BA_ "initialValue" SG_ 1762 sig_36_4 11.0;
BA_ "sendPeriod" BO_ 1121 100;
BA_ "crcStartValue" BO_ 1121 35;
BA_ "initialValue" SG_ 1121 sig_7_8 172.0;
BA_ "initialValue" SG_ 1121 sig_19_18 -5.842000000000001;
BA_ "initialValue" SG_ 1121 sig_23_3 -3.0;
BA_ "initialValue" SG_ 1121 sig_33_2 1.0;
BA_ "frameSendMode" BO_ 1648 2;
BA_ "sendPeriod" BO_ 1648 1000;
BA_ "eventMinDistance" BO_ 1648 1000;
BA_ "crcStartValue" BO_ 1648 208;
BA_ "initialValue" SG_ 1648 sig_8_15 5.485377660168382E-4;
BA_ "initialValue" SG_ 1648 sig_15_4 14.0;
BA_ "initialValue" SG_ 1648 sig_32_16 5.421477660168382E-4;
BA_ "sendPeriod" BO_ 627 25;
BA_ "crcStartValue" BO_ 627 80;
BA_ "initialValue" SG_ 627 sig_0_5 -2.162277660168379E-5;
BA_ "initialValue" SG_ 627 sig_32_23 715.8482660168381;
BA_ "initialValue" SG_ 627 sig_19_9 -89.22776601683796;
BA_ "initialValue" SG_ 627 sig_18_6 1.0;
BA_ "initialValue" SG_ 627 sig_34_6 22.377223398316207;
BA_ "sendPeriod" BO_ 1120 1000;
BA_ "crcStartValue" BO_ 1120 130;
BA_ "initialValue" SG_ 1120 sig_0_16 2.262177660168379;
BA_ "initialValue" SG_ 1120 sig_26_19 -4.367076601683781;
BA_ "initialValue" SG_ 1120 sig_25_2 -1.0;
BA_ "initialValue" SG_ 1120 sig_45_3 1.0;
BA_ "frameSendMode" BO_ 973 2;
BA_ "sendPeriod" BO_ 973 50;
BA_ "eventMinDistance" BO_ 973 50;
BA_ "crcStartValue" BO_ 973 243;
BA_ "initialValue" SG_ 973 sig_12_17 975.9922339831624;
BA_ "initialValue" SG_ 973 sig_8_1 1.0;
BA_ "initialValue" SG_ 973 sig_31_2 -1.0;
BA_ "initialValue" SG_ 973 sig_48_9 -1.0122776601683781E-4;
BA_ "initialValue" SG_ 973 sig_32_13 1.7497223398316213;
BA_ "initialValue" SG_ 973 sig_47_2 2.0;
BA_ "initialValue" SG_ 973 sig_45_1 1.0;
BA_ "initialValue" SG_ 973 sig_63_6 230.0;
BA_ "frameSendMode" BO_ 1362 2;
BA_ "sendPeriod" BO_ 1362 100;
BA_ "eventMinDistance" BO_ 1362 50;
BA_ "crcStartValue" BO_ 1362 135;
BA_ "initialValue" SG_ 1362 sig_21_9 3.96227766016838E-5;
BA_ "initialValue" SG_ 1362 sig_1_18 57423.0;
BA_ "initialValue" SG_ 1362 sig_20_2 -2.0;
BA_ "initialValue" SG_ 1362 sig_31_2 1.0;
BA_ "initialValue" SG_ 1362 sig_49_3 -4.0;
BA_ "initialValue" SG_ 1362 sig_47_2 2.0;
BA_ "sendPeriod" BO_ 897 100;
BA_ "crcStartValue" BO_ 897 109;
BA_ "initialValue" SG_ 897 sig_21_12 -84.0;
BA_ "initialValue" SG_ 897 sig_0_20 5.125637660168381E-4;
BA_ "initialValue" SG_ 897 sig_39_6 17.0;
BA_ "initialValue" SG_ 897 sig_40_2 -2.0;
BA_ "initialValue" SG_ 897 sig_63_7 70377.22339831622;
